VERSION "dbc-export 1 2025.20.8"

NS_ :

BS_:

BU_: ADSP APB APP APS APSB BB BMS CC CMP CMPD CP DAS DI DIF DIR DPB EPAS3P EPAS3S EPASTP EPASTS EPBL EPBR ESP EVSE FC GTW HCML HCMR HVP IBST ICR IDB LS OCS1P PARK PCS PM PMF PMR PNCD PTC RADC RCM RCM2 RCM3 RCU SCCM SCM SCS SDCR TAS TCU TPMS TRCM UI UIS UMC USM VC VCFRONT VCLEFT VCRIGHT VCSEC VEH

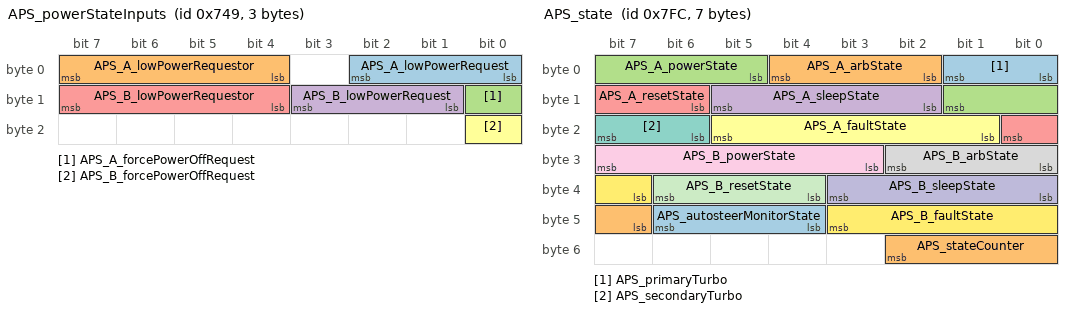
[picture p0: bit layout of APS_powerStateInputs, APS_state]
BO_ 1865 APS_powerStateInputs: 3 APS
 SG_ APS_A_lowPowerRequest : 0|3@1+ (1,0) [0|7] "" Vector__XXX
 SG_ APS_A_lowPowerRequestor : 4|4@1+ (1,0) [0|15] "" Vector__XXX
 SG_ APS_A_forcePowerOffRequest : 8|1@1+ (1,0) [0|1] "" Vector__XXX
 SG_ APS_B_lowPowerRequest : 9|3@1+ (1,0) [0|7] "" Vector__XXX
 SG_ APS_B_lowPowerRequestor : 12|4@1+ (1,0) [0|15] "" Vector__XXX
 SG_ APS_B_forcePowerOffRequest : 16|1@1+ (1,0) [0|1] "" Vector__XXX

BO_ 2044 APS_state: 7 APS
 SG_ APS_primaryTurbo : 0|2@1+ (1,0) [0|3] "" Vector__XXX
 SG_ APS_A_arbState : 2|3@1+ (1,0) [0|7] "" Vector__XXX
 SG_ APS_A_powerState : 5|5@1+ (1,0) [0|31] "" Vector__XXX
 SG_ APS_A_sleepState : 10|4@1+ (1,0) [0|15] "" Vector__XXX
 SG_ APS_A_resetState : 14|3@1+ (1,0) [0|7] "" Vector__XXX
 SG_ APS_A_faultState : 17|5@1+ (1,0) [0|31] "" Vector__XXX
 SG_ APS_secondaryTurbo : 22|2@1+ (1,0) [0|3] "" Vector__XXX
 SG_ APS_B_arbState : 24|3@1+ (1,0) [0|7] "" Vector__XXX
 SG_ APS_B_powerState : 27|5@1+ (1,0) [0|31] "" Vector__XXX
 SG_ APS_B_sleepState : 32|4@1+ (1,0) [0|15] "" Vector__XXX
 SG_ APS_B_resetState : 36|3@1+ (1,0) [0|7] "" Vector__XXX
 SG_ APS_B_faultState : 39|5@1+ (1,0) [0|31] "" Vector__XXX
 SG_ APS_autosteerMonitorState : 44|3@1+ (1,0) [0|7] "" Vector__XXX
 SG_ APS_stateCounter : 47|4@1+ (1,0) [0|15] "" Vector__XXX

BO_ 970 APS_status: 8 APS
 SG_ APS_appStatusMonitorState : 0|3@1+ (1,0) [0|7] "" Vector__XXX
 SG_ APS_vehBehaviorState : 4|4@1+ (1,0) [0|15] "" Vector__XXX
 SG_ APS_canMaster : 8|2@1+ (1,0) [0|2] "" Vector__XXX
 SG_ APS_appGpioState : 10|2@1+ (1,0) [0|3] "" Vector__XXX
 SG_ APS_eacInternalState : 12|3@1+ (1,0) [0|7] "" Vector__XXX
 SG_ APS_switchState : 15|1@1+ (1,0) [0|1] "" Vector__XXX
 SG_ APS_apbStatusMonitorState : 16|3@1+ (1,0) [0|7] "" Vector__XXX
 SG_ APS_apbGpioState : 20|2@1+ (1,0) [0|3] "" Vector__XXX
 SG_ APS_statusCounter : 22|4@1+ (1,0) [0|15] "" Vector__XXX
 SG_ APS_locLimitReason : 26|3@1+ (1,0) [0|7] "" Vector__XXX
 SG_ APS_appPowerStateRequest : 29|2@1+ (1,0) [0|3] "" Vector__XXX
 SG_ APS_appPowerStateReason : 31|4@1+ (1,0) [0|15] "" Vector__XXX
 SG_ APS_apbPowerStateRequest : 36|2@1+ (1,0) [0|3] "" Vector__XXX
 SG_ APS_apbPowerStateReason : 38|4@1+ (1,0) [0|15] "" Vector__XXX
 SG_ APS_heaterStateDebug : 43|3@1+ (1,0) [0|6] "" Vector__XXX
 SG_ APS_autosummonCounter : 46|3@1+ (1,0) [0|7] "" Vector__XXX
 SG_ APS_autosummonAlert : 49|1@1+ (1,0) [0|1] "" Vector__XXX
 SG_ APS_gpsAntennaState : 50|2@1+ (1,0) [0|3] "" Vector__XXX
 SG_ APS_arbState : 52|3@1+ (1,0) [0|7] "" Vector__XXX
 SG_ APS_socPowerOperatingMode : 55|2@1+ (1,0) [0|3] "" Vector__XXX
 SG_ APS_otherArbState : 57|3@1+ (1,0) [0|7] "" Vector__XXX

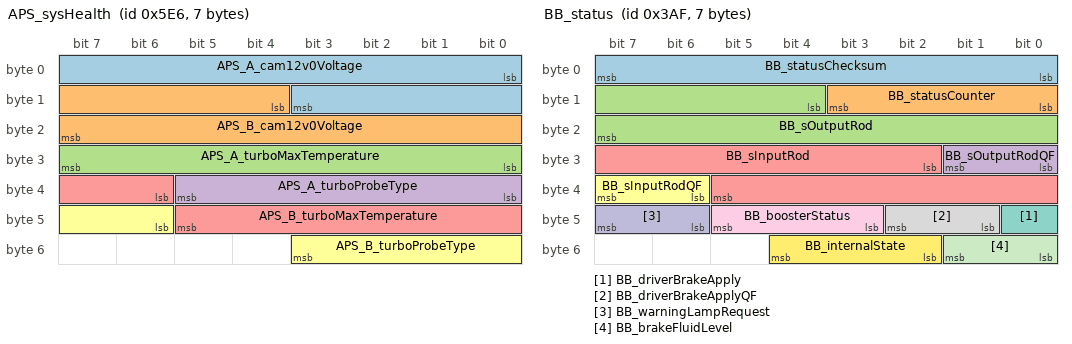
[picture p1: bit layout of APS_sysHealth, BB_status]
BO_ 1510 APS_sysHealth: 7 APS
 SG_ APS_A_cam12v0Voltage : 0|12@1+ (0.0048,0) [0|19.44] "V" Vector__XXX
 SG_ APS_B_cam12v0Voltage : 12|12@1+ (0.0048,0) [0|19.44] "V" Vector__XXX
 SG_ APS_A_turboMaxTemperature : 24|8@1- (1,0) [-128|127] "degC" Vector__XXX
 SG_ APS_A_turboProbeType : 32|6@1+ (1,0) [0|62] "" Vector__XXX
 SG_ APS_B_turboMaxTemperature : 38|8@1- (1,0) [-128|127] "degC" Vector__XXX
 SG_ APS_B_turboProbeType : 46|6@1+ (1,0) [0|62] "" Vector__XXX

BO_ 811 APS_warningMatrix0: 8 APS
 SG_ APS_w001_DEPRECATED : 0|1@1+ (1,0) [0|1] "" Vector__XXX
 SG_ APS_w002_ldwDisabled : 1|1@1+ (1,0) [0|1] "" Vector__XXX
 SG_ APS_w003_isaDisabled : 2|1@1+ (1,0) [0|1] "" Vector__XXX
 SG_ APS_w004_accDisabled : 3|1@1+ (1,0) [0|1] "" Vector__XXX
 SG_ APS_w005_fcwCancelled : 4|1@1+ (1,0) [0|1] "" Vector__XXX
 SG_ APS_w006_aebCancelled : 5|1@1+ (1,0) [0|1] "" Vector__XXX
 SG_ APS_w007_ahlbDisabled : 6|1@1+ (1,0) [0|1] "" Vector__XXX
 SG_ APS_w008_parkDisabled : 7|1@1+ (1,0) [0|1] "" Vector__XXX
 SG_ APS_w009_aebFault : 8|1@1+ (1,0) [0|1] "" Vector__XXX
 SG_ APS_w010_radcCalibIssue : 9|1@1+ (1,0) [0|1] "" Vector__XXX
 SG_ APS_w011_scaEvent : 10|1@1+ (1,0) [0|1] "" Vector__XXX
 SG_ APS_w012_Cam_BootFailure : 11|1@1+ (1,0) [0|1] "" Vector__XXX
 SG_ APS_w013_Cam_Watchdog : 12|1@1+ (1,0) [0|1] "" Vector__XXX
 SG_ APS_w014_swAssert : 13|1@1+ (1,0) [0|1] "" Vector__XXX
 SG_ APS_w015_Camera_Failsafes : 14|1@1+ (1,0) [0|1] "" Vector__XXX
 SG_ APS_w016_aeb_e_event : 15|1@1+ (1,0) [0|1] "" Vector__XXX
 SG_ APS_w017_Cam_Msg_MIA : 16|1@1+ (1,0) [0|1] "" Vector__XXX
 SG_ APS_w018_ECU_Power_Issue : 17|1@1+ (1,0) [0|1] "" Vector__XXX
 SG_ APS_w019_ECU_Stack_Overflow : 18|1@1+ (1,0) [0|1] "" Vector__XXX
 SG_ APS_w020_ECU_checkstopError : 19|1@1+ (1,0) [0|1] "" Vector__XXX
 SG_ APS_w021_ECU_Temperature_Issue : 20|1@1+ (1,0) [0|1] "" Vector__XXX
 SG_ APS_w022_ECU_EEPROM_Failure : 21|1@1+ (1,0) [0|1] "" Vector__XXX
 SG_ APS_w023_ECU_Cam_Statemismatc : 22|1@1+ (1,0) [0|1] "" Vector__XXX
 SG_ APS_w024_ECU_Watchdog_Reset : 23|1@1+ (1,0) [0|1] "" Vector__XXX
 SG_ APS_w025_LC_Steering_Override : 24|1@1+ (1,0) [0|1] "" Vector__XXX
 SG_ APS_w026_ECU_timingIssue : 25|1@1+ (1,0) [0|1] "" Vector__XXX
 SG_ APS_w027_ECU_Reset_Fault : 26|1@1+ (1,0) [0|1] "" Vector__XXX
 SG_ APS_w028_spi_rx_error : 27|1@1+ (1,0) [0|1] "" Vector__XXX
 SG_ APS_w029_spi_tx_error : 28|1@1+ (1,0) [0|1] "" Vector__XXX
 SG_ APS_w030_Heater_Issue : 29|1@1+ (1,0) [0|1] "" Vector__XXX
 SG_ APS_w031_canRxError : 30|1@1+ (1,0) [0|1] "" Vector__XXX
 SG_ APS_w032_canTxError : 31|1@1+ (1,0) [0|1] "" Vector__XXX
 SG_ APS_w033_gtwMia : 32|1@1+ (1,0) [0|1] "" Vector__XXX
 SG_ APS_w034_sccmMia : 33|1@1+ (1,0) [0|1] "" Vector__XXX
 SG_ APS_w035_espMia : 34|1@1+ (1,0) [0|1] "" Vector__XXX
 SG_ APS_w036_bdyMia : 35|1@1+ (1,0) [0|1] "" Vector__XXX
 SG_ APS_w037_camTacIssue : 36|1@1+ (1,0) [0|1] "" Vector__XXX
 SG_ APS_w038_camFailure : 37|1@1+ (1,0) [0|1] "" Vector__XXX
 SG_ APS_w039_sdm_rcm_Mia : 38|1@1+ (1,0) [0|1] "" Vector__XXX
 SG_ APS_w040_autopilotAngleSaturated : 39|1@1+ (1,0) [0|1] "" Vector__XXX
 SG_ APS_w041_autopilotRateSaturated : 40|1@1+ (1,0) [0|1] "" Vector__XXX
 SG_ APS_w042_autopilotAborting : 41|1@1+ (1,0) [0|1] "" Vector__XXX
 SG_ APS_w043_camLongRunTime : 42|1@1+ (1,0) [0|1] "" Vector__XXX
 SG_ APS_w044_appMobileyeFailure : 43|1@1+ (1,0) [0|1] "" Vector__XXX
 SG_ APS_w045_radMia : 44|1@1+ (1,0) [0|1] "" Vector__XXX
 SG_ APS_w046_eepromRecordAbsent : 45|1@1+ (1,0) [0|1] "" Vector__XXX
 SG_ APS_w047_edrEvent : 46|1@1+ (1,0) [0|1] "" Vector__XXX
 SG_ APS_w048_DAS_Features_Disabled : 47|1@1+ (1,0) [0|1] "" Vector__XXX
 SG_ APS_w049_eyeqVersionMismatch : 48|1@1+ (1,0) [0|1] "" Vector__XXX
 SG_ APS_w050_aeb_event : 49|1@1+ (1,0) [0|1] "" Vector__XXX
 SG_ APS_w051_radcEcuIssue : 50|1@1+ (1,0) [0|1] "" Vector__XXX
 SG_ APS_w052_radcSensorIssue : 51|1@1+ (1,0) [0|1] "" Vector__XXX
 SG_ APS_w053_radcCommIssue : 52|1@1+ (1,0) [0|1] "" Vector__XXX
 SG_ APS_w054_camAutofix : 53|1@1+ (1,0) [0|1] "" Vector__XXX
 SG_ APS_w055_radcVersionMismatch : 54|1@1+ (1,0) [0|1] "" Vector__XXX
 SG_ APS_w056_diMia : 55|1@1+ (1,0) [0|1] "" Vector__XXX
 SG_ APS_w057_mcuMia : 56|1@1+ (1,0) [0|1] "" Vector__XXX
 SG_ APS_w058_epbMia : 57|1@1+ (1,0) [0|1] "" Vector__XXX
 SG_ APS_w059_parkMia : 58|1@1+ (1,0) [0|1] "" Vector__XXX
 SG_ APS_w060_fcw_event : 59|1@1+ (1,0) [0|1] "" Vector__XXX
 SG_ APS_w061_tasMia : 60|1@1+ (1,0) [0|1] "" Vector__XXX
 SG_ APS_w062_radcAlignment : 61|1@1+ (1,0) [0|1] "" Vector__XXX
 SG_ APS_w063_parkVersionMismatch : 62|1@1+ (1,0) [0|1] "" Vector__XXX
 SG_ APS_w064_epasMia : 63|1@1+ (1,0) [0|1] "" Vector__XXX

BO_ 876 APS_warningMatrix1: 8 APS
 SG_ APS_w065_deserializerOvercurrent : 0|1@1+ (1,0) [0|1] "" Vector__XXX
 SG_ APS_w066_deserializerLockLost : 1|1@1+ (1,0) [0|1] "" Vector__XXX
 SG_ APS_w067_steeringAlignment : 2|1@1+ (1,0) [0|1] "" Vector__XXX
 SG_ APS_w068_vlInconsistency : 3|1@1+ (1,0) [0|1] "" Vector__XXX
 SG_ APS_w069_apcSpaceMasked : 4|1@1+ (1,0) [0|1] "" Vector__XXX
 SG_ APS_w070_apcIncompleteCal : 5|1@1+ (1,0) [0|1] "" Vector__XXX
 SG_ APS_w071_selfparkStarted : 6|1@1+ (1,0) [0|1] "" Vector__XXX
 SG_ APS_w072_selfparkComplete : 7|1@1+ (1,0) [0|1] "" Vector__XXX
 SG_ APS_w073_issueEscalatedLDW : 8|1@1+ (1,0) [0|1] "" Vector__XXX
 SG_ APS_w074_inPathStationaryObst : 9|1@1+ (1,0) [0|1] "" Vector__XXX
 SG_ APS_w075_scMia : 10|1@1+ (1,0) [0|1] "" Vector__XXX
 SG_ APS_w076_mobilEyeSetC : 11|1@1+ (1,0) [0|1] "" Vector__XXX
 SG_ APS_w077_pmmActive : 12|1@1+ (1,0) [0|1] "" Vector__XXX
 SG_ APS_w078_pmmActive2 : 13|1@1+ (1,0) [0|1] "" Vector__XXX
 SG_ APS_w079_edrAvailable : 14|1@1+ (1,0) [0|1] "" Vector__XXX
 SG_ APS_w080_accFailedActivation : 15|1@1+ (1,0) [0|1] "" Vector__XXX
 SG_ APS_w081_pmmActiveBraking : 16|1@1+ (1,0) [0|1] "" Vector__XXX
 SG_ APS_w082_inPathFSviolation : 17|1@1+ (1,0) [0|1] "" Vector__XXX
 SG_ APS_w083_inPathRADObject : 18|1@1+ (1,0) [0|1] "" Vector__XXX
 SG_ APS_w084_pmmIPSO : 19|1@1+ (1,0) [0|1] "" Vector__XXX
 SG_ APS_w085_pmmSteering : 20|1@1+ (1,0) [0|1] "" Vector__XXX
 SG_ APS_w086_robCollision : 21|1@1+ (1,0) [0|1] "" Vector__XXX
 SG_ APS_w087_DEPRECATED : 22|1@1+ (1,0) [0|1] "" Vector__XXX
 SG_ APS_w088_DEPRECATED : 23|1@1+ (1,0) [0|1] "" Vector__XXX
 SG_ APS_w089_DEPRECATED : 24|1@1+ (1,0) [0|1] "" Vector__XXX
 SG_ APS_w090_DEPRECATED : 25|1@1+ (1,0) [0|1] "" Vector__XXX
 SG_ APS_w091_DEPRECATED : 26|1@1+ (1,0) [0|1] "" Vector__XXX
 SG_ APS_w092_DEPRECATED : 27|1@1+ (1,0) [0|1] "" Vector__XXX
 SG_ APS_w093_DEPRECATED : 28|1@1+ (1,0) [0|1] "" Vector__XXX
 SG_ APS_w094_DEPRECATED : 29|1@1+ (1,0) [0|1] "" Vector__XXX
 SG_ APS_w095_DEPRECATED : 30|1@1+ (1,0) [0|1] "" Vector__XXX
 SG_ APS_w096_DEPRECATED : 31|1@1+ (1,0) [0|1] "" Vector__XXX
 SG_ APS_w097_DEPRECATED : 32|1@1+ (1,0) [0|1] "" Vector__XXX
 SG_ APS_w098_DEPRECATED : 33|1@1+ (1,0) [0|1] "" Vector__XXX
 SG_ APS_w099_DEPRECATED : 34|1@1+ (1,0) [0|1] "" Vector__XXX
 SG_ APS_w100_DEPRECATED : 35|1@1+ (1,0) [0|1] "" Vector__XXX
 SG_ APS_w101_DEPRECATED : 36|1@1+ (1,0) [0|1] "" Vector__XXX
 SG_ APS_w102_DEPRECATED : 37|1@1+ (1,0) [0|1] "" Vector__XXX
 SG_ APS_w103_robExperimentalAEB : 38|1@1+ (1,0) [0|1] "" Vector__XXX
 SG_ APS_w104_DEPRECATED : 39|1@1+ (1,0) [0|1] "" Vector__XXX
 SG_ APS_w105_DEPRECATED : 40|1@1+ (1,0) [0|1] "" Vector__XXX
 SG_ APS_w106_torsionBarOffset : 41|1@1+ (1,0) [0|1] "" Vector__XXX

BO_ 1113 APS_warningMatrix2: 8 APS
 SG_ APS_w129_ECU_Power_Issue : 0|1@1+ (1,0) [0|1] "" Vector__XXX
 SG_ APS_w130_ECU_Thermal_Issue : 1|1@1+ (1,0) [0|1] "" Vector__XXX
 SG_ APS_w131_trap_exception : 2|1@1+ (1,0) [0|1] "" Vector__XXX
 SG_ APS_w132_appVersionMismatch : 3|1@1+ (1,0) [0|1] "" Vector__XXX
 SG_ APS_w133_ETHSwitchError : 4|1@1+ (1,0) [0|1] "" Vector__XXX
 SG_ APS_w134_appMia : 5|1@1+ (1,0) [0|1] "" Vector__XXX
 SG_ APS_w135_appCritical : 6|1@1+ (1,0) [0|1] "" Vector__XXX
 SG_ APS_w136_gpsDisabled : 7|1@1+ (1,0) [0|1] "" Vector__XXX
 SG_ APS_w137_gpsFaultReset : 8|1@1+ (1,0) [0|1] "" Vector__XXX
 SG_ APS_w138_gpsComIssue : 9|1@1+ (1,0) [0|1] "" Vector__XXX
 SG_ APS_w139_udpBufferOverflow : 10|1@1+ (1,0) [0|1] "" Vector__XXX
 SG_ APS_w140_vcfrontMiaVehicleBus : 11|1@1+ (1,0) [0|1] "" Vector__XXX
 SG_ APS_w141_rcmMiaPartyBus : 12|1@1+ (1,0) [0|1] "" Vector__XXX
 SG_ APS_w142_diMiaPartyBus : 13|1@1+ (1,0) [0|1] "" Vector__XXX
 SG_ APS_w143_espMiaPartyBus : 14|1@1+ (1,0) [0|1] "" Vector__XXX
 SG_ APS_w144_vcleftMiaPartyBus : 15|1@1+ (1,0) [0|1] "" Vector__XXX
 SG_ APS_w145_vcrightMiaPartyBus : 16|1@1+ (1,0) [0|1] "" Vector__XXX
 SG_ APS_w146_epas3pMiaPartyBus : 17|1@1+ (1,0) [0|1] "" Vector__XXX
 SG_ APS_w147_vcleftMiaVehBus : 18|1@1+ (1,0) [0|1] "" Vector__XXX
 SG_ APS_w148_vcrightMiaVehBus : 19|1@1+ (1,0) [0|1] "" Vector__XXX
 SG_ APS_w149_epblMiaVehBus : 20|1@1+ (1,0) [0|1] "" Vector__XXX
 SG_ APS_w150_sccmMiaVehBus : 21|1@1+ (1,0) [0|1] "" Vector__XXX
 SG_ APS_w151_apRecovered : 22|1@1+ (1,0) [0|1] "" Vector__XXX
 SG_ APS_w152_gpsFusionStatus : 23|1@1+ (1,0) [0|1] "" Vector__XXX
 SG_ APS_w153_eacInhibit : 24|1@1+ (1,0) [0|1] "" Vector__XXX
 SG_ APS_w155_ethLwipError : 26|1@1+ (1,0) [0|1] "" Vector__XXX
 SG_ APS_w156_lwipAssert : 27|1@1+ (1,0) [0|1] "" Vector__XXX
 SG_ APS_w157_autopilotReboot : 28|1@1+ (1,0) [0|1] "" Vector__XXX
 SG_ APS_w158_apbMia : 29|1@1+ (1,0) [0|1] "" Vector__XXX
 SG_ APS_w159_apbCritical : 30|1@1+ (1,0) [0|1] "" Vector__XXX
 SG_ APS_w160_apbVersionMismatch : 31|1@1+ (1,0) [0|1] "" Vector__XXX
 SG_ APS_w161_gpsAntennaDisconnected : 32|1@1+ (1,0) [0|1] "" Vector__XXX
 SG_ APS_w162_TurboA_DisRegPgoodErr : 33|1@1+ (1,0) [0|1] "" Vector__XXX
 SG_ APS_w163_TurboA_DisRegNFault : 34|1@1+ (1,0) [0|1] "" Vector__XXX
 SG_ APS_w164_TurboA_12VFuseFault : 35|1@1+ (1,0) [0|1] "" Vector__XXX
 SG_ APS_w165_TurboA_Temp_NOS : 36|1@1+ (1,0) [0|1] "" Vector__XXX
 SG_ APS_w166_TurboA_SMSLockStepErr : 37|1@1+ (1,0) [0|1] "" Vector__XXX
 SG_ APS_w167_TurboA_TMU_Throttle : 38|1@1+ (1,0) [0|1] "" Vector__XXX
 SG_ APS_w168_TurboA_SMS_WDOG : 39|1@1+ (1,0) [0|1] "" Vector__XXX
 SG_ APS_w169_TurboA_SCS_LKUP : 40|1@1+ (1,0) [0|1] "" Vector__XXX
 SG_ APS_w170_TurboA_A72_watchdog : 41|1@1+ (1,0) [0|1] "" Vector__XXX
 SG_ APS_w171_TurboA_SMS_taskUtilErr : 42|1@1+ (1,0) [0|1] "" Vector__XXX
 SG_ APS_w172_apFeaturesUnavailable : 43|1@1+ (1,0) [0|1] "" Vector__XXX
 SG_ APS_w178_TurboB_DisRegPgoodErr : 49|1@1+ (1,0) [0|1] "" Vector__XXX
 SG_ APS_w179_TurboB_DisRegNFault : 50|1@1+ (1,0) [0|1] "" Vector__XXX
 SG_ APS_w180_TurboB_12VFuseFault : 51|1@1+ (1,0) [0|1] "" Vector__XXX
 SG_ APS_w181_TurboB_Temp_NOS : 52|1@1+ (1,0) [0|1] "" Vector__XXX
 SG_ APS_w182_TurboB_SMSLockStepErr : 53|1@1+ (1,0) [0|1] "" Vector__XXX
 SG_ APS_w183_TurboB_TMU_Throttle : 54|1@1+ (1,0) [0|1] "" Vector__XXX
 SG_ APS_w184_TurboB_SMS_WDOG : 55|1@1+ (1,0) [0|1] "" Vector__XXX
 SG_ APS_w185_TurboB_SCS_LKUP : 56|1@1+ (1,0) [0|1] "" Vector__XXX
 SG_ APS_w186_TurboB_A72_watchdog : 57|1@1+ (1,0) [0|1] "" Vector__XXX
 SG_ APS_w187_TurboB_SMS_taskUtilErr : 58|1@1+ (1,0) [0|1] "" Vector__XXX
 SG_ APS_w188_otherTurboUartMIA : 59|1@1+ (1,0) [0|1] "" Vector__XXX
 SG_ APS_w189_vcfrontMiaPartyBus : 60|1@1+ (1,0) [0|1] "" Vector__XXX
 SG_ APS_w190_iboosterMia : 61|1@1+ (1,0) [0|1] "" Vector__XXX
 SG_ APS_w191_timesyncError : 62|1@1+ (1,0) [0|1] "" Vector__XXX
 SG_ APS_w192_CANFault : 63|1@1+ (1,0) [0|1] "" Vector__XXX

BO_ 848 APS_warningMatrix3: 8 APS
 SG_ APS_w193_camWindshieldUnclean : 0|1@1+ (1,0) [0|1] "" Vector__XXX
 SG_ APS_w194_accDriverResumeRqrd : 1|1@1+ (1,0) [0|1] "" Vector__XXX
 SG_ APS_w195_scwUnavailable : 2|1@1+ (1,0) [0|1] "" Vector__XXX
 SG_ APS_w196_stopSignWarning : 3|1@1+ (1,0) [0|1] "" Vector__XXX
 SG_ APS_w197_redLightWarning : 4|1@1+ (1,0) [0|1] "" Vector__XXX
 SG_ APS_w198_tsrUnavailable : 5|1@1+ (1,0) [0|1] "" Vector__XXX
 SG_ APS_w199_apcAbort : 6|1@1+ (1,0) [0|1] "" Vector__XXX
 SG_ APS_w200_lcSlowdown : 7|1@1+ (1,0) [0|1] "" Vector__XXX
 SG_ APS_w201_lcAborting : 8|1@1+ (1,0) [0|1] "" Vector__XXX
 SG_ APS_w202_scwNoisyEnvironment : 9|1@1+ (1,0) [0|1] "" Vector__XXX
 SG_ APS_w203_apcActivation : 10|1@1+ (1,0) [0|1] "" Vector__XXX
 SG_ APS_w204_apcFinalFront : 11|1@1+ (1,0) [0|1] "" Vector__XXX
 SG_ APS_w205_apcFinalRear : 12|1@1+ (1,0) [0|1] "" Vector__XXX
 SG_ APS_w206_autosteerNotEnabled : 13|1@1+ (1,0) [0|1] "" Vector__XXX
 SG_ APS_w207_autosteerUnavailable : 14|1@1+ (1,0) [0|1] "" Vector__XXX
 SG_ APS_w208_rackDetected : 15|1@1+ (1,0) [0|1] "" Vector__XXX
 SG_ APS_w209_autoSummonRequest : 16|1@1+ (1,0) [0|1] "" Vector__XXX
 SG_ APS_w210_camObstrcted : 17|1@1+ (1,0) [0|1] "" Vector__XXX
 SG_ APS_w211_accNoSeatBelt : 18|1@1+ (1,0) [0|1] "" Vector__XXX
 SG_ APS_w212_lcUnavailableStrikeOut : 19|1@1+ (1,0) [0|1] "" Vector__XXX
 SG_ APS_w213_autosteerStruckOut : 20|1@1+ (1,0) [0|1] "" Vector__XXX
 SG_ APS_w214_driverNotIntracting : 21|1@1+ (1,0) [0|1] "" Vector__XXX
 SG_ APS_w215_contDriverNotIntracting : 22|1@1+ (1,0) [0|1] "" Vector__XXX
 SG_ APS_w216_driverOverriding : 23|1@1+ (1,0) [0|1] "" Vector__XXX
 SG_ APS_w217_lcUnavailableSpeeding : 24|1@1+ (1,0) [0|1] "" Vector__XXX
 SG_ APS_w218_lcSpeedExceededLimit : 25|1@1+ (1,0) [0|1] "" Vector__XXX
 SG_ APS_w219_lcTempUnavailableSpeed : 26|1@1+ (1,0) [0|1] "" Vector__XXX
 SG_ APS_w220_lcTempUnavailableRoad : 27|1@1+ (1,0) [0|1] "" Vector__XXX
 SG_ APS_w221_accRadarBlind : 28|1@1+ (1,0) [0|1] "" Vector__XXX
 SG_ APS_w222_accCameraBlind : 29|1@1+ (1,0) [0|1] "" Vector__XXX
 SG_ APS_w223_accObjectInPath : 30|1@1+ (1,0) [0|1] "" Vector__XXX
 SG_ APS_w224_accCameraCalibration : 31|1@1+ (1,0) [0|1] "" Vector__XXX
 SG_ APS_w225_lcDegradedVisSpeedLmt : 32|1@1+ (1,0) [0|1] "" Vector__XXX
 SG_ APS_w226_lcCamCalNeededSpeedLmt : 33|1@1+ (1,0) [0|1] "" Vector__XXX
 SG_ APS_w227_virtualWallBlocked : 34|1@1+ (1,0) [0|1] "" Vector__XXX
 SG_ APS_w228_DEPRECATED : 35|1@1+ (1,0) [0|1] "" Vector__XXX
 SG_ APS_w229_alcUltrasoundDamaged : 36|1@1+ (1,0) [0|1] "" Vector__XXX
 SG_ APS_w230_alcUltrasoundBlocked : 37|1@1+ (1,0) [0|1] "" Vector__XXX
 SG_ APS_w231_idfEvent : 38|1@1+ (1,0) [0|1] "" Vector__XXX
 SG_ APS_w232_laneChangeRequested : 39|1@1+ (1,0) [0|1] "" Vector__XXX
 SG_ APS_w235_a72LoopDetected : 42|1@1+ (1,0) [0|1] "" Vector__XXX
 SG_ APS_w236_canSharedMemError : 43|1@1+ (1,0) [0|1] "" Vector__XXX
 SG_ APS_w237_faultMgrEventDetected : 44|1@1+ (1,0) [0|1] "" Vector__XXX
 SG_ APS_w238_resetReason : 45|1@1+ (1,0) [0|1] "" Vector__XXX
 SG_ APS_w241_ddrInitFailures : 48|1@1+ (1,0) [0|1] "" Vector__XXX
 SG_ APS_w242_tripMBISTFailure : 49|1@1+ (1,0) [0|1] "" Vector__XXX
 SG_ APS_w243_tripHWErrorStatus : 50|1@1+ (1,0) [0|1] "" Vector__XXX
 SG_ APS_w244_gpuHWFaultStatus : 51|1@1+ (1,0) [0|1] "" Vector__XXX
 SG_ APS_w245_eloopRxFromUnexpectedSo : 52|1@1+ (1,0) [0|1] "" Vector__XXX
 SG_ APS_w246_ethloopSwitchPortLinkDo : 53|1@1+ (1,0) [0|1] "" Vector__XXX
 SG_ APS_w247_ethernetFrameError : 54|1@1+ (1,0) [0|1] "" Vector__XXX
 SG_ APS_w248_ethloopSwitchPoorSqi : 55|1@1+ (1,0) [0|1] "" Vector__XXX
 SG_ APS_w249_ufsFailures : 56|1@1+ (1,0) [0|1] "" Vector__XXX
 SG_ APS_w250_ethloopSwitchMemUsageTo : 57|1@1+ (1,0) [0|1] "" Vector__XXX
 SG_ APS_w251_ethloopSwitchMemUsageTo : 58|1@1+ (1,0) [0|1] "" Vector__XXX
 SG_ APS_w252_ethSwitchPortLinkDown : 59|1@1+ (1,0) [0|1] "" Vector__XXX
 SG_ APS_w253_powerStateTimeout : 60|1@1+ (1,0) [0|1] "" Vector__XXX
 SG_ APS_w254_sleepStateTimeout : 61|1@1+ (1,0) [0|1] "" Vector__XXX
 SG_ APS_w255_bootHealth : 62|1@1+ (1,0) [0|1] "" Vector__XXX

BO_ 784 APS_warningMatrix4: 8 APS
 SG_ APS_w257_assertFailure : 0|1@1+ (1,0) [0|1] "" Vector__XXX
 SG_ APS_w258_qspiFlashSectorChecksum : 1|1@1+ (1,0) [0|1] "" Vector__XXX
 SG_ APS_w259_qspiFailure : 2|1@1+ (1,0) [0|1] "" Vector__XXX
 SG_ APS_w260_pgoodFailure : 3|1@1+ (1,0) [0|1] "" Vector__XXX
 SG_ APS_w261_vrmFaultGrpA : 4|1@1+ (1,0) [0|1] "" Vector__XXX
 SG_ APS_w262_vrmFaultGrpB : 5|1@1+ (1,0) [0|1] "" Vector__XXX
 SG_ APS_w263_vrmFaultGrpC : 6|1@1+ (1,0) [0|1] "" Vector__XXX
 SG_ APS_w264_ddrPhy0Failures : 7|1@1+ (1,0) [0|1] "" Vector__XXX
 SG_ APS_w265_ddrPhy1Failures : 8|1@1+ (1,0) [0|1] "" Vector__XXX
 SG_ APS_w266_ddrPhy2Failures : 9|1@1+ (1,0) [0|1] "" Vector__XXX
 SG_ APS_w267_ddrPhy3Failures : 10|1@1+ (1,0) [0|1] "" Vector__XXX
 SG_ APS_w268_ddrControllerFailures : 11|1@1+ (1,0) [0|1] "" Vector__XXX
 SG_ APS_w269_ethSwitchRxPageCountToo : 12|1@1+ (1,0) [0|1] "" Vector__XXX
 SG_ APS_w270_ethSwitchRxPageCountToo : 13|1@1+ (1,0) [0|1] "" Vector__XXX
 SG_ APS_w271_ddrScheduler0EccErrors : 14|1@1+ (1,0) [0|1] "" Vector__XXX
 SG_ APS_w272_ddrScheduler1EccErrors : 15|1@1+ (1,0) [0|1] "" Vector__XXX
 SG_ APS_w273_ddrScheduler2EccErrors : 16|1@1+ (1,0) [0|1] "" Vector__XXX
 SG_ APS_w274_ddrScheduler3EccErrors : 17|1@1+ (1,0) [0|1] "" Vector__XXX
 SG_ APS_w275_ddrScheduler4EccErrors : 18|1@1+ (1,0) [0|1] "" Vector__XXX
 SG_ APS_w276_ddrScheduler5EccErrors : 19|1@1+ (1,0) [0|1] "" Vector__XXX
 SG_ APS_w277_ddrScheduler6EccErrors : 20|1@1+ (1,0) [0|1] "" Vector__XXX
 SG_ APS_w278_ddrScheduler7EccErrors : 21|1@1+ (1,0) [0|1] "" Vector__XXX
 SG_ APS_w279_ufsPartitionError : 22|1@1+ (1,0) [0|1] "" Vector__XXX
 SG_ APS_w280_pepsMia : 23|1@1+ (1,0) [0|1] "" Vector__XXX
 SG_ APS_w281_rsaMia : 24|1@1+ (1,0) [0|1] "" Vector__XXX
 SG_ APS_w282_smmuError : 25|1@1+ (1,0) [0|1] "" Vector__XXX
 SG_ APS_w284_cam12VBuckBoostAPwrIssu : 27|1@1+ (1,0) [0|1] "" Vector__XXX
 SG_ APS_w285_cam12VBuckBoostBPwrIssu : 28|1@1+ (1,0) [0|1] "" Vector__XXX
 SG_ APS_w286_cam12VEFuseAPrimaryIssu : 29|1@1+ (1,0) [0|1] "" Vector__XXX
 SG_ APS_w287_cam12VEFuseASecondaryIs : 30|1@1+ (1,0) [0|1] "" Vector__XXX
 SG_ APS_w288_brakeboosterMia : 31|1@1+ (1,0) [0|1] "" Vector__XXX
 SG_ APS_w289_turboTemperatureWarning : 32|1@1+ (1,0) [0|1] "" Vector__XXX
 SG_ APS_w290_cam12VBuckBoostBPwrRing : 33|1@1+ (1,0) [0|1] "" Vector__XXX

BO_ 943 BB_status: 7 BB
 SG_ BB_statusChecksum : 0|8@1+ (1,0) [0|255] "" Vector__XXX
 SG_ BB_statusCounter : 8|4@1+ (1,0) [0|15] "" Vector__XXX
 SG_ BB_sOutputRod : 12|12@1+ (0.015625,-5) [-5|47] "mm" Vector__XXX
 SG_ BB_sOutputRodQF : 24|2@1+ (1,0) [0|3] "" Vector__XXX
 SG_ BB_sInputRod : 26|12@1+ (0.015625,-5) [-5|47] "mm" Vector__XXX
 SG_ BB_sInputRodQF : 38|2@1+ (1,0) [0|3] "" Vector__XXX
 SG_ BB_driverBrakeApply : 40|1@1+ (1,0) [0|1] "" Vector__XXX
 SG_ BB_driverBrakeApplyQF : 41|2@1+ (1,0) [0|3] "" Vector__XXX
 SG_ BB_boosterStatus : 43|3@1+ (1,0) [0|7] "" Vector__XXX
 SG_ BB_warningLampRequest : 46|2@1+ (1,0) [0|3] "" Vector__XXX
 SG_ BB_brakeFluidLevel : 48|2@1+ (1,0) [0|3] "" Vector__XXX
 SG_ BB_internalState : 50|3@1+ (1,0) [0|7] "" Vector__XXX

BO_TX_BU_ 1865 : APS;
BO_TX_BU_ 2044 : APS;
BO_TX_BU_ 970 : APS;
BO_TX_BU_ 1510 : APS;
BO_TX_BU_ 811 : APS;
BO_TX_BU_ 876 : APS;
BO_TX_BU_ 1113 : APS;
BO_TX_BU_ 848 : APS;
BO_TX_BU_ 784 : APS;
BO_TX_BU_ 943 : BB;
CM_ BO_ 1865 "Driver assistance computer (secondary) message: power state inputs";
CM_ SG_ 1865 APS_A_lowPowerRequest "Indicates Autopilot Secondary Processor (APS) low power state request presence.";
CM_ SG_ 1865 APS_A_lowPowerRequestor "Indicates who initiated the Autopilot Secondary Processor (APS) low power request.";
CM_ SG_ 1865 APS_A_forcePowerOffRequest "Driver assistance computer (secondary): a force power off request";
CM_ SG_ 1865 APS_B_lowPowerRequest "Indicates Autopilot Secondary Processor (APS) low power state request presence.";
CM_ SG_ 1865 APS_B_lowPowerRequestor "Indicates who initiated the Autopilot Secondary Processor (APS) low power request.";
CM_ SG_ 1865 APS_B_forcePowerOffRequest "Driver assistance computer (secondary): b force power off request";
CM_ BO_ 2044 "Driver assistance computer (secondary) message: state";
CM_ SG_ 2044 APS_primaryTurbo "Which of the two Turbos currently holds the primary role.";
CM_ SG_ 2044 APS_A_arbState "The state of the arbitration state machine of Turbo A.";
CM_ SG_ 2044 APS_A_powerState "The state of the power state machine of Turbo A.";
CM_ SG_ 2044 APS_A_sleepState "The state of the sleep state machine of Turbo A.";
CM_ SG_ 2044 APS_A_resetState "The state of the reset state machine of Turbo A.";
CM_ SG_ 2044 APS_A_faultState "The state of the fault state machine of Turbo A.";
CM_ SG_ 2044 APS_secondaryTurbo "Which of the two Turbos currently holds the secondary role.";
CM_ SG_ 2044 APS_B_arbState "The state of the arbitration state machine of Turbo B.";
CM_ SG_ 2044 APS_B_powerState "The state of the power state machine of Turbo B.";
CM_ SG_ 2044 APS_B_sleepState "The state of the sleep state machine of Turbo B.";
CM_ SG_ 2044 APS_B_resetState "The state of the reset state machine of Turbo B.";
CM_ SG_ 2044 APS_B_faultState "The state of the fault state machine of Turbo B.";
CM_ SG_ 2044 APS_autosteerMonitorState "Driver assistance computer (secondary): autosteer monitor state";
CM_ SG_ 2044 APS_stateCounter "Driver assistance computer (secondary): state counter";
CM_ BO_ 970 "Driver assistance computer (secondary) message: status";
CM_ SG_ 970 APS_appStatusMonitorState "The current status of APE, indicates the health of the stack on the APE";
CM_ SG_ 970 APS_vehBehaviorState "Driver assistance computer (secondary): veh behavior state";
CM_ SG_ 970 APS_canMaster "Indicates which of the autopilot computers is currently controlling outgoing CAN traffic.; raw 3 = signal not available (SNA)";
CM_ SG_ 970 APS_appGpioState "The GPIO state of APEA, indicates the health of the primary Parker (HW2 and HW2.5)";
CM_ SG_ 970 APS_eacInternalState "Indicates the internal state of the external angle control monitor running on Aurix.";
CM_ SG_ 970 APS_switchState "Driver assistance computer (secondary): switch state";
CM_ SG_ 970 APS_apbStatusMonitorState "The current status of APEB, indicates the health of the stack on the APEB";
CM_ SG_ 970 APS_apbGpioState "The GPIO state of APEB, indicates the health of the secondary Parker (HW2.5 only)";
CM_ SG_ 970 APS_statusCounter "Driver assistance computer (secondary): status counter";
CM_ SG_ 970 APS_locLimitReason "Indicates why longitudinal control limits are currently not relaxed";
CM_ SG_ 970 APS_appPowerStateRequest "Indicates ap primary power state request";
CM_ SG_ 970 APS_appPowerStateReason "Indicates ap primary power state reason";
CM_ SG_ 970 APS_apbPowerStateRequest "Indicates ap backup power state request";
CM_ SG_ 970 APS_apbPowerStateReason "Indicates ap backup power state reason";
CM_ SG_ 970 APS_heaterStateDebug "Driver assistance computer (secondary): heater state debug; raw 7 = signal not available (SNA)";
CM_ SG_ 970 APS_autosummonCounter "Driver assistance computer (secondary): autosummon counter";
CM_ SG_ 970 APS_autosummonAlert "Driver assistance computer (secondary): autosummon alert";
CM_ SG_ 970 APS_gpsAntennaState "Driver assistance computer (secondary): gps antenna state";
CM_ SG_ 970 APS_arbState "Reports the state of the arbitration state machine of this System on Chip (SoC).";
CM_ SG_ 970 APS_socPowerOperatingMode "Reports the total number of System on Chips (SoCs) that are powered on to provide support for active Autopilot features.";
CM_ SG_ 970 APS_otherArbState "Reports the state of the arbitration state machine of the other System on Chip (SoC). Lets the current SoC know the state of the other SoC to achieve safer operations.";
CM_ BO_ 1510 "Driver assistance computer (secondary) message: sys health";
CM_ SG_ 1510 APS_A_cam12v0Voltage "Measures the 12V camera power supply voltage for Autopilot Secondary Processor (APS) Turbo A; raw 4095 = signal not available (SNA)";
CM_ SG_ 1510 APS_B_cam12v0Voltage "Measures the 12V camera power supply voltage for Autopilot Secondary Processor (APS) Turbo B; raw 4095 = signal not available (SNA)";
CM_ SG_ 1510 APS_A_turboMaxTemperature "Reports the maximum temperature recorded by Autopilot Secondary Processor (APS) unit A.; raw 128 = signal not available (SNA)";
CM_ SG_ 1510 APS_A_turboProbeType "Driver assistance computer (secondary): a turbo probe type; raw 63 = signal not available (SNA)";
CM_ SG_ 1510 APS_B_turboMaxTemperature "Reports the maximum temperature recorded by Autopilot Secondary Processor (APS) unit B.; raw 128 = signal not available (SNA)";
CM_ SG_ 1510 APS_B_turboProbeType "Driver assistance computer (secondary): b turbo probe type; raw 63 = signal not available (SNA)";
CM_ BO_ 811 "Driver assistance computer (secondary) message: warning matrix0";
CM_ SG_ 811 APS_w001_DEPRECATED "Driver assistance computer (secondary): w001 DEPRECATED";
CM_ SG_ 811 APS_w002_ldwDisabled "Driver assistance computer (secondary): w002 ldw disabled";
CM_ SG_ 811 APS_w003_isaDisabled "Driver assistance computer (secondary): w003 isa disabled";
CM_ SG_ 811 APS_w004_accDisabled "Driver assistance computer (secondary): w004 acc disabled";
CM_ SG_ 811 APS_w005_fcwCancelled "Driver assistance computer (secondary): w005 fcw cancelled";
CM_ SG_ 811 APS_w006_aebCancelled "Driver assistance computer (secondary): w006 aeb cancelled";
CM_ SG_ 811 APS_w007_ahlbDisabled "Driver assistance computer (secondary): w007 ahlb disabled";
CM_ SG_ 811 APS_w008_parkDisabled "Driver assistance computer (secondary): w008 park disabled";
CM_ SG_ 811 APS_w009_aebFault "Driver assistance computer (secondary): w009 aeb fault";
CM_ SG_ 811 APS_w010_radcCalibIssue "Driver assistance computer (secondary): w010 radc calib issue";
CM_ SG_ 811 APS_w011_scaEvent "Driver assistance computer (secondary): w011 sca event";
CM_ SG_ 811 APS_w012_Cam_BootFailure "Driver assistance computer (secondary): w012 cam boot failure";
CM_ SG_ 811 APS_w013_Cam_Watchdog "Driver assistance computer (secondary): w013 cam watchdog";
CM_ SG_ 811 APS_w014_swAssert "Driver assistance computer (secondary): w014 sw assert";
CM_ SG_ 811 APS_w015_Camera_Failsafes "Driver assistance computer (secondary): w015 camera failsafes";
CM_ SG_ 811 APS_w016_aeb_e_event "Driver assistance computer (secondary): w016 aeb e event";
CM_ SG_ 811 APS_w017_Cam_Msg_MIA "Driver assistance computer (secondary): w017 cam msg MIA";
CM_ SG_ 811 APS_w018_ECU_Power_Issue "Driver assistance computer (secondary): w018 ECU power issue";
CM_ SG_ 811 APS_w019_ECU_Stack_Overflow "Driver assistance computer (secondary): w019 ECU stack overflow";
CM_ SG_ 811 APS_w020_ECU_checkstopError "Driver assistance computer (secondary): w020 ECU checkstop error";
CM_ SG_ 811 APS_w021_ECU_Temperature_Issue "Driver assistance computer (secondary): w021 ECU temperature issue";
CM_ SG_ 811 APS_w022_ECU_EEPROM_Failure "Driver assistance computer (secondary): w022 ECU EEPROM failure";
CM_ SG_ 811 APS_w023_ECU_Cam_Statemismatc "Driver assistance computer (secondary): w023 ECU cam statemismatc";
CM_ SG_ 811 APS_w024_ECU_Watchdog_Reset "Driver assistance computer (secondary): w024 ECU watchdog reset";
CM_ SG_ 811 APS_w025_LC_Steering_Override "Driver assistance computer (secondary): w025 LC steering override";
CM_ SG_ 811 APS_w026_ECU_timingIssue "Driver assistance computer (secondary): w026 ECU timing issue";
CM_ SG_ 811 APS_w027_ECU_Reset_Fault "Driver assistance computer (secondary): w027 ECU reset fault";
CM_ SG_ 811 APS_w028_spi_rx_error "Driver assistance computer (secondary): w028 spi rx error";
CM_ SG_ 811 APS_w029_spi_tx_error "Driver assistance computer (secondary): w029 spi tx error";
CM_ SG_ 811 APS_w030_Heater_Issue "Driver assistance computer (secondary): w030 heater issue";
CM_ SG_ 811 APS_w031_canRxError "Driver assistance computer (secondary): w031 can rx error";
CM_ SG_ 811 APS_w032_canTxError "Driver assistance computer (secondary): w032 can tx error";
CM_ SG_ 811 APS_w033_gtwMia "Driver assistance computer (secondary): w033 gtw mia";
CM_ SG_ 811 APS_w034_sccmMia "Driver assistance computer (secondary): w034 sccm mia";
CM_ SG_ 811 APS_w035_espMia "Driver assistance computer (secondary): w035 esp mia";
CM_ SG_ 811 APS_w036_bdyMia "Driver assistance computer (secondary): w036 bdy mia";
CM_ SG_ 811 APS_w037_camTacIssue "Driver assistance computer (secondary): w037 cam tac issue";
CM_ SG_ 811 APS_w038_camFailure "Driver assistance computer (secondary): w038 cam failure";
CM_ SG_ 811 APS_w039_sdm_rcm_Mia "Driver assistance computer (secondary): w039 sdm rcm mia";
CM_ SG_ 811 APS_w040_autopilotAngleSaturated "Driver assistance computer (secondary): w040 autopilot angle saturated";
CM_ SG_ 811 APS_w041_autopilotRateSaturated "Driver assistance computer (secondary): w041 autopilot rate saturated";
CM_ SG_ 811 APS_w042_autopilotAborting "Driver assistance computer (secondary): w042 autopilot aborting";
CM_ SG_ 811 APS_w043_camLongRunTime "Driver assistance computer (secondary): w043 cam long run time";
CM_ SG_ 811 APS_w044_appMobileyeFailure "Driver assistance computer (secondary): w044 app mobileye failure";
CM_ SG_ 811 APS_w045_radMia "Driver assistance computer (secondary): w045 rad mia";
CM_ SG_ 811 APS_w046_eepromRecordAbsent "Driver assistance computer (secondary): w046 eeprom record absent";
CM_ SG_ 811 APS_w047_edrEvent "Driver assistance computer (secondary): w047 edr event";
CM_ SG_ 811 APS_w048_DAS_Features_Disabled "Driver assistance computer (secondary): w048 DAS features disabled";
CM_ SG_ 811 APS_w049_eyeqVersionMismatch "Driver assistance computer (secondary): w049 eyeq version mismatch";
CM_ SG_ 811 APS_w050_aeb_event "Driver assistance computer (secondary): w050 aeb event";
CM_ SG_ 811 APS_w051_radcEcuIssue "Driver assistance computer (secondary): w051 radc ecu issue";
CM_ SG_ 811 APS_w052_radcSensorIssue "Driver assistance computer (secondary): w052 radc sensor issue";
CM_ SG_ 811 APS_w053_radcCommIssue "Driver assistance computer (secondary): w053 radc comm issue";
CM_ SG_ 811 APS_w054_camAutofix "Driver assistance computer (secondary): w054 cam autofix";
CM_ SG_ 811 APS_w055_radcVersionMismatch "Driver assistance computer (secondary): w055 radc version mismatch";
CM_ SG_ 811 APS_w056_diMia "Driver assistance computer (secondary): w056 di mia";
CM_ SG_ 811 APS_w057_mcuMia "Driver assistance computer (secondary): w057 mcu mia";
CM_ SG_ 811 APS_w058_epbMia "Driver assistance computer (secondary): w058 epb mia";
CM_ SG_ 811 APS_w059_parkMia "Driver assistance computer (secondary): w059 park mia";
CM_ SG_ 811 APS_w060_fcw_event "Driver assistance computer (secondary): w060 fcw event";
CM_ SG_ 811 APS_w061_tasMia "Driver assistance computer (secondary): w061 tas mia";
CM_ SG_ 811 APS_w062_radcAlignment "Driver assistance computer (secondary): w062 radc alignment";
CM_ SG_ 811 APS_w063_parkVersionMismatch "Driver assistance computer (secondary): w063 park version mismatch";
CM_ SG_ 811 APS_w064_epasMia "Driver assistance computer (secondary): w064 epas mia";
CM_ BO_ 876 "Driver assistance computer (secondary) message: warning matrix1";
CM_ SG_ 876 APS_w065_deserializerOvercurrent "Driver assistance computer (secondary): w065 deserializer overcurrent";
CM_ SG_ 876 APS_w066_deserializerLockLost "Driver assistance computer (secondary): w066 deserializer lock lost";
CM_ SG_ 876 APS_w067_steeringAlignment "Driver assistance computer (secondary): w067 steering alignment";
CM_ SG_ 876 APS_w068_vlInconsistency "Driver assistance computer (secondary): w068 vl inconsistency";
CM_ SG_ 876 APS_w069_apcSpaceMasked "Driver assistance computer (secondary): w069 apc space masked";
CM_ SG_ 876 APS_w070_apcIncompleteCal "Driver assistance computer (secondary): w070 apc incomplete cal";
CM_ SG_ 876 APS_w071_selfparkStarted "Driver assistance computer (secondary): w071 selfpark started";
CM_ SG_ 876 APS_w072_selfparkComplete "Driver assistance computer (secondary): w072 selfpark complete";
CM_ SG_ 876 APS_w073_issueEscalatedLDW "Driver assistance computer (secondary): w073 issue escalated LDW";
CM_ SG_ 876 APS_w074_inPathStationaryObst "Driver assistance computer (secondary): w074 in path stationary obst";
CM_ SG_ 876 APS_w075_scMia "Driver assistance computer (secondary): w075 sc mia";
CM_ SG_ 876 APS_w076_mobilEyeSetC "Driver assistance computer (secondary): w076 mobil eye set c";
CM_ SG_ 876 APS_w077_pmmActive "Driver assistance computer (secondary): w077 pmm active";
CM_ SG_ 876 APS_w078_pmmActive2 "Driver assistance computer (secondary): w078 pmm active2";
CM_ SG_ 876 APS_w079_edrAvailable "Driver assistance computer (secondary): w079 edr available";
CM_ SG_ 876 APS_w080_accFailedActivation "Driver assistance computer (secondary): w080 acc failed activation";
CM_ SG_ 876 APS_w081_pmmActiveBraking "Driver assistance computer (secondary): w081 pmm active braking";
CM_ SG_ 876 APS_w082_inPathFSviolation "Driver assistance computer (secondary): w082 in path f sviolation";
CM_ SG_ 876 APS_w083_inPathRADObject "Driver assistance computer (secondary): w083 in path RAD object";
CM_ SG_ 876 APS_w084_pmmIPSO "Driver assistance computer (secondary): w084 pmm IPSO";
CM_ SG_ 876 APS_w085_pmmSteering "Driver assistance computer (secondary): w085 pmm steering";
CM_ SG_ 876 APS_w086_robCollision "Driver assistance computer (secondary): w086 rob collision";
CM_ SG_ 876 APS_w087_DEPRECATED "Driver assistance computer (secondary): w087 DEPRECATED";
CM_ SG_ 876 APS_w088_DEPRECATED "Driver assistance computer (secondary): w088 DEPRECATED";
CM_ SG_ 876 APS_w089_DEPRECATED "Driver assistance computer (secondary): w089 DEPRECATED";
CM_ SG_ 876 APS_w090_DEPRECATED "Driver assistance computer (secondary): w090 DEPRECATED";
CM_ SG_ 876 APS_w091_DEPRECATED "Driver assistance computer (secondary): w091 DEPRECATED";
CM_ SG_ 876 APS_w092_DEPRECATED "Driver assistance computer (secondary): w092 DEPRECATED";
CM_ SG_ 876 APS_w093_DEPRECATED "Driver assistance computer (secondary): w093 DEPRECATED";
CM_ SG_ 876 APS_w094_DEPRECATED "Driver assistance computer (secondary): w094 DEPRECATED";
CM_ SG_ 876 APS_w095_DEPRECATED "Driver assistance computer (secondary): w095 DEPRECATED";
CM_ SG_ 876 APS_w096_DEPRECATED "Driver assistance computer (secondary): w096 DEPRECATED";
CM_ SG_ 876 APS_w097_DEPRECATED "Driver assistance computer (secondary): w097 DEPRECATED";
CM_ SG_ 876 APS_w098_DEPRECATED "Driver assistance computer (secondary): w098 DEPRECATED";
CM_ SG_ 876 APS_w099_DEPRECATED "Driver assistance computer (secondary): w099 DEPRECATED";
CM_ SG_ 876 APS_w100_DEPRECATED "Driver assistance computer (secondary): w100 DEPRECATED";
CM_ SG_ 876 APS_w101_DEPRECATED "Driver assistance computer (secondary): w101 DEPRECATED";
CM_ SG_ 876 APS_w102_DEPRECATED "Driver assistance computer (secondary): w102 DEPRECATED";
CM_ SG_ 876 APS_w103_robExperimentalAEB "Driver assistance computer (secondary): w103 rob experimental AEB";
CM_ SG_ 876 APS_w104_DEPRECATED "Driver assistance computer (secondary): w104 DEPRECATED";
CM_ SG_ 876 APS_w105_DEPRECATED "Driver assistance computer (secondary): w105 DEPRECATED";
CM_ SG_ 876 APS_w106_torsionBarOffset "Driver assistance computer (secondary): w106 torsion bar offset";
CM_ BO_ 1113 "Driver assistance computer (secondary) message: warning matrix2";
CM_ SG_ 1113 APS_w129_ECU_Power_Issue "Driver assistance computer (secondary): w129 ECU power issue";
CM_ SG_ 1113 APS_w130_ECU_Thermal_Issue "Driver assistance computer (secondary): w130 ECU thermal issue";
CM_ SG_ 1113 APS_w131_trap_exception "Driver assistance computer (secondary): w131 trap exception";
CM_ SG_ 1113 APS_w132_appVersionMismatch "Driver assistance computer (secondary): w132 app version mismatch";
CM_ SG_ 1113 APS_w133_ETHSwitchError "Driver assistance computer (secondary): w133 ETH switch error";
CM_ SG_ 1113 APS_w134_appMia "Driver assistance computer (secondary): w134 app mia";
CM_ SG_ 1113 APS_w135_appCritical "Driver assistance computer (secondary): w135 app critical";
CM_ SG_ 1113 APS_w136_gpsDisabled "Driver assistance computer (secondary): w136 gps disabled";
CM_ SG_ 1113 APS_w137_gpsFaultReset "Driver assistance computer (secondary): w137 gps fault reset";
CM_ SG_ 1113 APS_w138_gpsComIssue "Driver assistance computer (secondary): w138 gps com issue";
CM_ SG_ 1113 APS_w139_udpBufferOverflow "Driver assistance computer (secondary): w139 udp buffer overflow";
CM_ SG_ 1113 APS_w140_vcfrontMiaVehicleBus "Driver assistance computer (secondary): w140 vcfront mia vehicle bus";
CM_ SG_ 1113 APS_w141_rcmMiaPartyBus "Driver assistance computer (secondary): w141 rcm mia party bus";
CM_ SG_ 1113 APS_w142_diMiaPartyBus "Driver assistance computer (secondary): w142 di mia party bus";
CM_ SG_ 1113 APS_w143_espMiaPartyBus "Driver assistance computer (secondary): w143 esp mia party bus";
CM_ SG_ 1113 APS_w144_vcleftMiaPartyBus "Driver assistance computer (secondary): w144 vcleft mia party bus";
CM_ SG_ 1113 APS_w145_vcrightMiaPartyBus "Driver assistance computer (secondary): w145 vcright mia party bus";
CM_ SG_ 1113 APS_w146_epas3pMiaPartyBus "Driver assistance computer (secondary): w146 epas3p mia party bus";
CM_ SG_ 1113 APS_w147_vcleftMiaVehBus "Driver assistance computer (secondary): w147 vcleft mia veh bus";
CM_ SG_ 1113 APS_w148_vcrightMiaVehBus "Driver assistance computer (secondary): w148 vcright mia veh bus";
CM_ SG_ 1113 APS_w149_epblMiaVehBus "Driver assistance computer (secondary): w149 epbl mia veh bus";
CM_ SG_ 1113 APS_w150_sccmMiaVehBus "Driver assistance computer (secondary): w150 sccm mia veh bus";
CM_ SG_ 1113 APS_w151_apRecovered "Driver assistance computer (secondary): w151 ap recovered";
CM_ SG_ 1113 APS_w152_gpsFusionStatus "Driver assistance computer (secondary): w152 gps fusion status";
CM_ SG_ 1113 APS_w153_eacInhibit "Driver assistance computer (secondary): w153 eac inhibit";
CM_ SG_ 1113 APS_w155_ethLwipError "Driver assistance computer (secondary): w155 eth lwip error";
CM_ SG_ 1113 APS_w156_lwipAssert "Driver assistance computer (secondary): w156 lwip assert";
CM_ SG_ 1113 APS_w157_autopilotReboot "Driver assistance computer (secondary): w157 autopilot reboot";
CM_ SG_ 1113 APS_w158_apbMia "Driver assistance computer (secondary): w158 apb mia";
CM_ SG_ 1113 APS_w159_apbCritical "Driver assistance computer (secondary): w159 apb critical";
CM_ SG_ 1113 APS_w160_apbVersionMismatch "Driver assistance computer (secondary): w160 apb version mismatch";
CM_ SG_ 1113 APS_w161_gpsAntennaDisconnected "Driver assistance computer (secondary): w161 gps antenna disconnected";
CM_ SG_ 1113 APS_w162_TurboA_DisRegPgoodErr "Driver assistance computer (secondary): w162 turbo a dis reg pgood err";
CM_ SG_ 1113 APS_w163_TurboA_DisRegNFault "Driver assistance computer (secondary): w163 turbo a dis reg n fault";
CM_ SG_ 1113 APS_w164_TurboA_12VFuseFault "Driver assistance computer (secondary): w164 turbo a 12 v fuse fault";
CM_ SG_ 1113 APS_w165_TurboA_Temp_NOS "Driver assistance computer (secondary): w165 turbo a temp NOS";
CM_ SG_ 1113 APS_w166_TurboA_SMSLockStepErr "Driver assistance computer (secondary): w166 turbo a SMS lock step err";
CM_ SG_ 1113 APS_w167_TurboA_TMU_Throttle "Driver assistance computer (secondary): w167 turbo a TMU throttle";
CM_ SG_ 1113 APS_w168_TurboA_SMS_WDOG "Driver assistance computer (secondary): w168 turbo a SMS WDOG";
CM_ SG_ 1113 APS_w169_TurboA_SCS_LKUP "Driver assistance computer (secondary): w169 turbo a SCS LKUP";
CM_ SG_ 1113 APS_w170_TurboA_A72_watchdog "Driver assistance computer (secondary): w170 turbo a A72 watchdog";
CM_ SG_ 1113 APS_w171_TurboA_SMS_taskUtilErr "Driver assistance computer (secondary): w171 turbo a SMS task util err";
CM_ SG_ 1113 APS_w172_apFeaturesUnavailable "Driver assistance computer (secondary): w172 ap features unavailable";
CM_ SG_ 1113 APS_w178_TurboB_DisRegPgoodErr "Driver assistance computer (secondary): w178 turbo b dis reg pgood err";
CM_ SG_ 1113 APS_w179_TurboB_DisRegNFault "Driver assistance computer (secondary): w179 turbo b dis reg n fault";
CM_ SG_ 1113 APS_w180_TurboB_12VFuseFault "Driver assistance computer (secondary): w180 turbo b 12 v fuse fault";
CM_ SG_ 1113 APS_w181_TurboB_Temp_NOS "Driver assistance computer (secondary): w181 turbo b temp NOS";
CM_ SG_ 1113 APS_w182_TurboB_SMSLockStepErr "Driver assistance computer (secondary): w182 turbo b SMS lock step err";
CM_ SG_ 1113 APS_w183_TurboB_TMU_Throttle "Driver assistance computer (secondary): w183 turbo b TMU throttle";
CM_ SG_ 1113 APS_w184_TurboB_SMS_WDOG "Driver assistance computer (secondary): w184 turbo b SMS WDOG";
CM_ SG_ 1113 APS_w185_TurboB_SCS_LKUP "Driver assistance computer (secondary): w185 turbo b SCS LKUP";
CM_ SG_ 1113 APS_w186_TurboB_A72_watchdog "Driver assistance computer (secondary): w186 turbo b A72 watchdog";
CM_ SG_ 1113 APS_w187_TurboB_SMS_taskUtilErr "Driver assistance computer (secondary): w187 turbo b SMS task util err";
CM_ SG_ 1113 APS_w188_otherTurboUartMIA "Driver assistance computer (secondary): w188 other turbo uart MIA";
CM_ SG_ 1113 APS_w189_vcfrontMiaPartyBus "Driver assistance computer (secondary): w189 vcfront mia party bus";
CM_ SG_ 1113 APS_w190_iboosterMia "Driver assistance computer (secondary): w190 ibooster mia";
CM_ SG_ 1113 APS_w191_timesyncError "Driver assistance computer (secondary): w191 timesync error";
CM_ SG_ 1113 APS_w192_CANFault "Driver assistance computer (secondary): w192 CAN fault";
CM_ BO_ 848 "Driver assistance computer (secondary) message: warning matrix3";
CM_ SG_ 848 APS_w193_camWindshieldUnclean "Driver assistance computer (secondary): w193 cam windshield unclean";
CM_ SG_ 848 APS_w194_accDriverResumeRqrd "Driver assistance computer (secondary): w194 acc driver resume rqrd";
CM_ SG_ 848 APS_w195_scwUnavailable "Driver assistance computer (secondary): w195 scw unavailable";
CM_ SG_ 848 APS_w196_stopSignWarning "Driver assistance computer (secondary): w196 stop sign warning";
CM_ SG_ 848 APS_w197_redLightWarning "Driver assistance computer (secondary): w197 red light warning";
CM_ SG_ 848 APS_w198_tsrUnavailable "Driver assistance computer (secondary): w198 tsr unavailable";
CM_ SG_ 848 APS_w199_apcAbort "Driver assistance computer (secondary): w199 apc abort";
CM_ SG_ 848 APS_w200_lcSlowdown "Driver assistance computer (secondary): w200 lc slowdown";
CM_ SG_ 848 APS_w201_lcAborting "Driver assistance computer (secondary): w201 lc aborting";
CM_ SG_ 848 APS_w202_scwNoisyEnvironment "Driver assistance computer (secondary): w202 scw noisy environment";
CM_ SG_ 848 APS_w203_apcActivation "Driver assistance computer (secondary): w203 apc activation";
CM_ SG_ 848 APS_w204_apcFinalFront "Driver assistance computer (secondary): w204 apc final front";
CM_ SG_ 848 APS_w205_apcFinalRear "Driver assistance computer (secondary): w205 apc final rear";
CM_ SG_ 848 APS_w206_autosteerNotEnabled "Driver assistance computer (secondary): w206 autosteer not enabled";
CM_ SG_ 848 APS_w207_autosteerUnavailable "Driver assistance computer (secondary): w207 autosteer unavailable";
CM_ SG_ 848 APS_w208_rackDetected "Driver assistance computer (secondary): w208 rack detected";
CM_ SG_ 848 APS_w209_autoSummonRequest "Driver assistance computer (secondary): w209 auto summon request";
CM_ SG_ 848 APS_w210_camObstrcted "Driver assistance computer (secondary): w210 cam obstrcted";
CM_ SG_ 848 APS_w211_accNoSeatBelt "Driver assistance computer (secondary): w211 acc no seat belt";
CM_ SG_ 848 APS_w212_lcUnavailableStrikeOut "Driver assistance computer (secondary): w212 lc unavailable strike out";
CM_ SG_ 848 APS_w213_autosteerStruckOut "Driver assistance computer (secondary): w213 autosteer struck out";
CM_ SG_ 848 APS_w214_driverNotIntracting "Driver assistance computer (secondary): w214 driver not intracting";
CM_ SG_ 848 APS_w215_contDriverNotIntracting "Driver assistance computer (secondary): w215 cont driver not intracting";
CM_ SG_ 848 APS_w216_driverOverriding "Driver assistance computer (secondary): w216 driver overriding";
CM_ SG_ 848 APS_w217_lcUnavailableSpeeding "Driver assistance computer (secondary): w217 lc unavailable speeding";
CM_ SG_ 848 APS_w218_lcSpeedExceededLimit "Driver assistance computer (secondary): w218 lc speed exceeded limit";
CM_ SG_ 848 APS_w219_lcTempUnavailableSpeed "Driver assistance computer (secondary): w219 lc temp unavailable speed";
CM_ SG_ 848 APS_w220_lcTempUnavailableRoad "Driver assistance computer (secondary): w220 lc temp unavailable road";
CM_ SG_ 848 APS_w221_accRadarBlind "Driver assistance computer (secondary): w221 acc radar blind";
CM_ SG_ 848 APS_w222_accCameraBlind "Driver assistance computer (secondary): w222 acc camera blind";
CM_ SG_ 848 APS_w223_accObjectInPath "Driver assistance computer (secondary): w223 acc object in path";
CM_ SG_ 848 APS_w224_accCameraCalibration "Driver assistance computer (secondary): w224 acc camera calibration";
CM_ SG_ 848 APS_w225_lcDegradedVisSpeedLmt "Driver assistance computer (secondary): w225 lc degraded vis speed lmt";
CM_ SG_ 848 APS_w226_lcCamCalNeededSpeedLmt "Driver assistance computer (secondary): w226 lc cam cal needed speed lmt";
CM_ SG_ 848 APS_w227_virtualWallBlocked "Driver assistance computer (secondary): w227 virtual wall blocked";
CM_ SG_ 848 APS_w228_DEPRECATED "Driver assistance computer (secondary): w228 DEPRECATED";
CM_ SG_ 848 APS_w229_alcUltrasoundDamaged "Driver assistance computer (secondary): w229 alc ultrasound damaged";
CM_ SG_ 848 APS_w230_alcUltrasoundBlocked "Driver assistance computer (secondary): w230 alc ultrasound blocked";
CM_ SG_ 848 APS_w231_idfEvent "Driver assistance computer (secondary): w231 idf event";
CM_ SG_ 848 APS_w232_laneChangeRequested "Driver assistance computer (secondary): w232 lane change requested";
CM_ SG_ 848 APS_w235_a72LoopDetected "Driver assistance computer (secondary): w235 a72 loop detected";
CM_ SG_ 848 APS_w236_canSharedMemError "Driver assistance computer (secondary): w236 can shared mem error";
CM_ SG_ 848 APS_w237_faultMgrEventDetected "Driver assistance computer (secondary): w237 fault mgr event detected";
CM_ SG_ 848 APS_w238_resetReason "Driver assistance computer (secondary): w238 reset reason";
CM_ SG_ 848 APS_w241_ddrInitFailures "Driver assistance computer (secondary): w241 ddr init failures";
CM_ SG_ 848 APS_w242_tripMBISTFailure "Driver assistance computer (secondary): w242 trip MBIST failure";
CM_ SG_ 848 APS_w243_tripHWErrorStatus "Driver assistance computer (secondary): w243 trip HW error status";
CM_ SG_ 848 APS_w244_gpuHWFaultStatus "Driver assistance computer (secondary): w244 gpu HW fault status";
CM_ SG_ 848 APS_w245_eloopRxFromUnexpectedSo "Driver assistance computer (secondary): w245 eloop rx from unexpected source MAC";
CM_ SG_ 848 APS_w246_ethloopSwitchPortLinkDo "Driver assistance computer (secondary): w246 ethloop switch port link down";
CM_ SG_ 848 APS_w247_ethernetFrameError "Driver assistance computer (secondary): w247 ethernet frame error";
CM_ SG_ 848 APS_w248_ethloopSwitchPoorSqi "Driver assistance computer (secondary): w248 ethloop switch poor sqi";
CM_ SG_ 848 APS_w249_ufsFailures "Driver assistance computer (secondary): w249 ufs failures";
CM_ SG_ 848 APS_w250_ethloopSwitchMemUsageTo "Driver assistance computer (secondary): w250 ethloop switch mem usage too high port2";
CM_ SG_ 848 APS_w251_ethloopSwitchMemUsageTo "Driver assistance computer (secondary): w251 ethloop switch mem usage too high port3";
CM_ SG_ 848 APS_w252_ethSwitchPortLinkDown "Driver assistance computer (secondary): w252 eth switch port link down";
CM_ SG_ 848 APS_w253_powerStateTimeout "Driver assistance computer (secondary): w253 power state timeout";
CM_ SG_ 848 APS_w254_sleepStateTimeout "Driver assistance computer (secondary): w254 sleep state timeout";
CM_ SG_ 848 APS_w255_bootHealth "Driver assistance computer (secondary): w255 boot health";
CM_ BO_ 784 "Driver assistance computer (secondary) message: warning matrix4";
CM_ SG_ 784 APS_w257_assertFailure "Driver assistance computer (secondary): w257 assert failure";
CM_ SG_ 784 APS_w258_qspiFlashSectorChecksum "Driver assistance computer (secondary): w258 qspi flash sector checksum mismatch";
CM_ SG_ 784 APS_w259_qspiFailure "Driver assistance computer (secondary): w259 qspi failure";
CM_ SG_ 784 APS_w260_pgoodFailure "Driver assistance computer (secondary): w260 pgood failure";
CM_ SG_ 784 APS_w261_vrmFaultGrpA "Driver assistance computer (secondary): w261 vrm fault grp a";
CM_ SG_ 784 APS_w262_vrmFaultGrpB "Driver assistance computer (secondary): w262 vrm fault grp b";
CM_ SG_ 784 APS_w263_vrmFaultGrpC "Driver assistance computer (secondary): w263 vrm fault grp c";
CM_ SG_ 784 APS_w264_ddrPhy0Failures "Driver assistance computer (secondary): w264 ddr phy0 failures";
CM_ SG_ 784 APS_w265_ddrPhy1Failures "Driver assistance computer (secondary): w265 ddr phy1 failures";
CM_ SG_ 784 APS_w266_ddrPhy2Failures "Driver assistance computer (secondary): w266 ddr phy2 failures";
CM_ SG_ 784 APS_w267_ddrPhy3Failures "Driver assistance computer (secondary): w267 ddr phy3 failures";
CM_ SG_ 784 APS_w268_ddrControllerFailures "Driver assistance computer (secondary): w268 ddr controller failures";
CM_ SG_ 784 APS_w269_ethSwitchRxPageCountToo "Driver assistance computer (secondary): w269 eth switch rx page count too high port0 3";
CM_ SG_ 784 APS_w270_ethSwitchRxPageCountToo "Driver assistance computer (secondary): w270 eth switch rx page count too high port4 7";
CM_ SG_ 784 APS_w271_ddrScheduler0EccErrors "Driver assistance computer (secondary): w271 ddr scheduler0 ecc errors";
CM_ SG_ 784 APS_w272_ddrScheduler1EccErrors "Driver assistance computer (secondary): w272 ddr scheduler1 ecc errors";
CM_ SG_ 784 APS_w273_ddrScheduler2EccErrors "Driver assistance computer (secondary): w273 ddr scheduler2 ecc errors";
CM_ SG_ 784 APS_w274_ddrScheduler3EccErrors "Driver assistance computer (secondary): w274 ddr scheduler3 ecc errors";
CM_ SG_ 784 APS_w275_ddrScheduler4EccErrors "Driver assistance computer (secondary): w275 ddr scheduler4 ecc errors";
CM_ SG_ 784 APS_w276_ddrScheduler5EccErrors "Driver assistance computer (secondary): w276 ddr scheduler5 ecc errors";
CM_ SG_ 784 APS_w277_ddrScheduler6EccErrors "Driver assistance computer (secondary): w277 ddr scheduler6 ecc errors";
CM_ SG_ 784 APS_w278_ddrScheduler7EccErrors "Driver assistance computer (secondary): w278 ddr scheduler7 ecc errors";
CM_ SG_ 784 APS_w279_ufsPartitionError "Driver assistance computer (secondary): w279 ufs partition error";
CM_ SG_ 784 APS_w280_pepsMia "Driver assistance computer (secondary): w280 peps mia";
CM_ SG_ 784 APS_w281_rsaMia "Driver assistance computer (secondary): w281 rsa mia";
CM_ SG_ 784 APS_w282_smmuError "Driver assistance computer (secondary): w282 smmu error";
CM_ SG_ 784 APS_w284_cam12VBuckBoostAPwrIssu "Driver assistance computer (secondary): w284 cam12 v buck boost a pwr issue";
CM_ SG_ 784 APS_w285_cam12VBuckBoostBPwrIssu "Driver assistance computer (secondary): w285 cam12 v buck boost b pwr issue";
CM_ SG_ 784 APS_w286_cam12VEFuseAPrimaryIssu "Driver assistance computer (secondary): w286 cam12 VE fuse a primary issue";
CM_ SG_ 784 APS_w287_cam12VEFuseASecondaryIs "Driver assistance computer (secondary): w287 cam12 VE fuse a secondary issue";
CM_ SG_ 784 APS_w288_brakeboosterMia "Driver assistance computer (secondary): w288 brakebooster mia";
CM_ SG_ 784 APS_w289_turboTemperatureWarning "Driver assistance computer (secondary): w289 turbo temperature warning";
CM_ SG_ 784 APS_w290_cam12VBuckBoostBPwrRing "Driver assistance computer (secondary): w290 cam12 v buck boost b pwr ringing";
CM_ BO_ 943 "BB ECU message: status";
CM_ SG_ 943 BB_statusChecksum "BB ECU: status checksum";
CM_ SG_ 943 BB_statusCounter "BB ECU: status counter";
CM_ SG_ 943 BB_sOutputRod "Reports the measured brake booster (BB) plunger piston position";
CM_ SG_ 943 BB_sOutputRodQF "Reports the BB_sOutputRod signal qualifier";
CM_ SG_ 943 BB_sInputRod "Reports the measured brake booster (BB) input rod stroke.";
CM_ SG_ 943 BB_sInputRodQF "Reports the BB_sInputRod signal qualifier.";
CM_ SG_ 943 BB_driverBrakeApply "Indicates whether the driver operates the brake pedal. Only active when the driver brakes, not when an external brake command implemented on brake booster (BB).";
CM_ SG_ 943 BB_driverBrakeApplyQF "Qualifier for BB_driverBrakeApply";
CM_ SG_ 943 BB_boosterStatus "Indication of the brake booster (BB) functional state";
CM_ SG_ 943 BB_warningLampRequest "Request from brake booster (BB) to enable the red brake lamp";
CM_ SG_ 943 BB_brakeFluidLevel "Indication of the brake fluid reservoir fluid level sensor status measured by the brake booster (BB).";
CM_ SG_ 943 BB_internalState "Indication of the brake booster (BB) internal state";
BA_DEF_ BO_ "GenMsgCycleTime" INT 0 3600000;
BA_DEF_ BO_ "GenMsgSendType" ENUM "Cyclic","NotUsed","NotUsed","NotUsed","NotUsed","NotUsed","NotUsed","IfActive","NoMsgSendType","NotUsed";
BA_DEF_ BO_ "VFrameFormat" ENUM "StandardCAN","ExtendedCAN","reserved","J1939PG","reserved","reserved","reserved","reserved","reserved","reserved","reserved","reserved","reserved","reserved","StandardCAN_FD","ExtendedCAN_FD";
BA_DEF_ BO_ "CANFD_BRS" ENUM "0","1";
BA_DEF_ SG_ "GenSigSNA" STRING;
BA_DEF_ SG_ "SystemSignalLongSymbol" STRING;
BA_DEF_ SG_ "Confidence" ENUM "validated","plausible","layout-only","contradicted";
BA_DEF_DEF_ "GenMsgCycleTime" 0;
BA_DEF_DEF_ "GenMsgSendType" "NoMsgSendType";
BA_DEF_DEF_ "VFrameFormat" "StandardCAN";
BA_DEF_DEF_ "CANFD_BRS" "1";
BA_DEF_DEF_ "GenSigSNA" "";
BA_DEF_DEF_ "SystemSignalLongSymbol" "";
BA_DEF_DEF_ "Confidence" "layout-only";
BA_ "GenMsgCycleTime" BO_ 1865 100;
BA_ "GenMsgSendType" BO_ 1865 0;
BA_ "GenMsgCycleTime" BO_ 2044 100;
BA_ "GenMsgSendType" BO_ 2044 0;
BA_ "GenMsgCycleTime" BO_ 970 500;
BA_ "GenMsgSendType" BO_ 970 0;
BA_ "GenMsgCycleTime" BO_ 1510 1000;
BA_ "GenMsgSendType" BO_ 1510 0;
BA_ "GenMsgCycleTime" BO_ 811 1000;
BA_ "GenMsgSendType" BO_ 811 0;
BA_ "GenMsgCycleTime" BO_ 876 1000;
BA_ "GenMsgSendType" BO_ 876 0;
BA_ "GenMsgCycleTime" BO_ 1113 1000;
BA_ "GenMsgSendType" BO_ 1113 0;
BA_ "GenMsgCycleTime" BO_ 848 1000;
BA_ "GenMsgSendType" BO_ 848 0;
BA_ "GenMsgCycleTime" BO_ 784 1000;
BA_ "GenMsgSendType" BO_ 784 0;
BA_ "GenMsgCycleTime" BO_ 943 10;
BA_ "GenMsgSendType" BO_ 943 0;
BA_ "Confidence" SG_ 1865 APS_A_lowPowerRequest 0;
BA_ "Confidence" SG_ 1865 APS_A_lowPowerRequestor 0;
BA_ "Confidence" SG_ 1865 APS_A_forcePowerOffRequest 0;
BA_ "Confidence" SG_ 1865 APS_B_lowPowerRequest 0;
BA_ "Confidence" SG_ 1865 APS_B_lowPowerRequestor 0;
BA_ "Confidence" SG_ 1865 APS_B_forcePowerOffRequest 0;
BA_ "Confidence" SG_ 2044 APS_primaryTurbo 0;
BA_ "Confidence" SG_ 2044 APS_A_arbState 0;
BA_ "Confidence" SG_ 2044 APS_A_powerState 0;
BA_ "Confidence" SG_ 2044 APS_A_sleepState 0;
BA_ "Confidence" SG_ 2044 APS_A_resetState 0;
BA_ "Confidence" SG_ 2044 APS_A_faultState 0;
BA_ "Confidence" SG_ 2044 APS_secondaryTurbo 0;
BA_ "Confidence" SG_ 2044 APS_B_arbState 0;
BA_ "Confidence" SG_ 2044 APS_B_powerState 0;
BA_ "Confidence" SG_ 2044 APS_B_sleepState 0;
BA_ "Confidence" SG_ 2044 APS_B_resetState 0;
BA_ "Confidence" SG_ 2044 APS_B_faultState 0;
BA_ "Confidence" SG_ 2044 APS_autosteerMonitorState 1;
BA_ "Confidence" SG_ 970 APS_appStatusMonitorState 0;
BA_ "Confidence" SG_ 970 APS_vehBehaviorState 0;
BA_ "Confidence" SG_ 970 APS_canMaster 0;
BA_ "GenSigSNA" SG_ 970 APS_canMaster "3";
BA_ "Confidence" SG_ 970 APS_appGpioState 0;
BA_ "Confidence" SG_ 970 APS_eacInternalState 0;
BA_ "Confidence" SG_ 970 APS_switchState 0;
BA_ "Confidence" SG_ 970 APS_apbStatusMonitorState 0;
BA_ "Confidence" SG_ 970 APS_apbGpioState 0;
BA_ "Confidence" SG_ 970 APS_statusCounter 0;
BA_ "Confidence" SG_ 970 APS_locLimitReason 0;
BA_ "Confidence" SG_ 970 APS_appPowerStateRequest 0;
BA_ "Confidence" SG_ 970 APS_appPowerStateReason 0;
BA_ "Confidence" SG_ 970 APS_apbPowerStateRequest 1;
BA_ "Confidence" SG_ 970 APS_apbPowerStateReason 1;
BA_ "Confidence" SG_ 970 APS_heaterStateDebug 1;
BA_ "GenSigSNA" SG_ 970 APS_heaterStateDebug "7";
BA_ "Confidence" SG_ 970 APS_gpsAntennaState 1;
BA_ "Confidence" SG_ 970 APS_arbState 1;
BA_ "Confidence" SG_ 970 APS_socPowerOperatingMode 1;
BA_ "Confidence" SG_ 970 APS_otherArbState 1;
BA_ "Confidence" SG_ 1510 APS_A_cam12v0Voltage 0;
BA_ "GenSigSNA" SG_ 1510 APS_A_cam12v0Voltage "4095";
BA_ "Confidence" SG_ 1510 APS_B_cam12v0Voltage 0;
BA_ "GenSigSNA" SG_ 1510 APS_B_cam12v0Voltage "4095";
BA_ "Confidence" SG_ 1510 APS_A_turboMaxTemperature 0;
BA_ "GenSigSNA" SG_ 1510 APS_A_turboMaxTemperature "128";
BA_ "Confidence" SG_ 1510 APS_A_turboProbeType 0;
BA_ "GenSigSNA" SG_ 1510 APS_A_turboProbeType "63";
BA_ "Confidence" SG_ 1510 APS_B_turboMaxTemperature 0;
BA_ "GenSigSNA" SG_ 1510 APS_B_turboMaxTemperature "128";
BA_ "Confidence" SG_ 1510 APS_B_turboProbeType 0;
BA_ "GenSigSNA" SG_ 1510 APS_B_turboProbeType "63";
BA_ "SystemSignalLongSymbol" SG_ 848 APS_w245_eloopRxFromUnexpectedSo "APS_w245_eloopRxFromUnexpectedSourceMAC";
BA_ "SystemSignalLongSymbol" SG_ 848 APS_w246_ethloopSwitchPortLinkDo "APS_w246_ethloopSwitchPortLinkDown";
BA_ "SystemSignalLongSymbol" SG_ 848 APS_w250_ethloopSwitchMemUsageTo "APS_w250_ethloopSwitchMemUsageTooHighPort2";
BA_ "SystemSignalLongSymbol" SG_ 848 APS_w251_ethloopSwitchMemUsageTo "APS_w251_ethloopSwitchMemUsageTooHighPort3";
BA_ "SystemSignalLongSymbol" SG_ 784 APS_w258_qspiFlashSectorChecksum "APS_w258_qspiFlashSectorChecksumMismatch";
BA_ "SystemSignalLongSymbol" SG_ 784 APS_w269_ethSwitchRxPageCountToo "APS_w269_ethSwitchRxPageCountTooHighPort0_3";
BA_ "SystemSignalLongSymbol" SG_ 784 APS_w270_ethSwitchRxPageCountToo "APS_w270_ethSwitchRxPageCountTooHighPort4_7";
BA_ "SystemSignalLongSymbol" SG_ 784 APS_w284_cam12VBuckBoostAPwrIssu "APS_w284_cam12VBuckBoostAPwrIssue";
BA_ "SystemSignalLongSymbol" SG_ 784 APS_w285_cam12VBuckBoostBPwrIssu "APS_w285_cam12VBuckBoostBPwrIssue";
BA_ "SystemSignalLongSymbol" SG_ 784 APS_w286_cam12VEFuseAPrimaryIssu "APS_w286_cam12VEFuseAPrimaryIssue";
BA_ "SystemSignalLongSymbol" SG_ 784 APS_w287_cam12VEFuseASecondaryIs "APS_w287_cam12VEFuseASecondaryIssue";
BA_ "SystemSignalLongSymbol" SG_ 784 APS_w290_cam12VBuckBoostBPwrRing "APS_w290_cam12VBuckBoostBPwrRinging";
BA_ "Confidence" SG_ 943 BB_statusChecksum 0;
BA_ "Confidence" SG_ 943 BB_statusCounter 0;
BA_ "Confidence" SG_ 943 BB_sOutputRod 0;
BA_ "Confidence" SG_ 943 BB_sOutputRodQF 0;
BA_ "Confidence" SG_ 943 BB_sInputRod 0;
BA_ "Confidence" SG_ 943 BB_sInputRodQF 0;
BA_ "Confidence" SG_ 943 BB_driverBrakeApply 0;
BA_ "Confidence" SG_ 943 BB_driverBrakeApplyQF 0;
BA_ "Confidence" SG_ 943 BB_boosterStatus 0;
BA_ "Confidence" SG_ 943 BB_warningLampRequest 0;
BA_ "Confidence" SG_ 943 BB_brakeFluidLevel 0;
BA_ "Confidence" SG_ 943 BB_internalState 0;
VAL_ 1865 APS_A_lowPowerRequest 5 "APS_LOW_POWER_COLD_RESET" 4 "APS_LOW_POWER_SOC_WARM_RESET" 3 "APS_LOW_POWER_AP_WARM_RESET" 2 "APS_LOW_POWER_OFF" 1 "APS_LOW_POWER_SUSPEND" 0 "APS_LOW_POWER_NONE" ;
VAL_ 1865 APS_A_lowPowerRequestor 10 "APS_LOW_POWER_REQ_COUNT" 9 "APS_LOW_POWER_REQ_SGK_PGOOD_IRQ" 8 "APS_LOW_POWER_REQ_SGK_CONSOLE" 7 "APS_LOW_POWER_REQ_SGK_SLEEP" 6 "APS_LOW_POWER_REQ_SGK_UDS" 5 "APS_LOW_POWER_REQ_SGK_BRIDGE" 4 "APS_LOW_POWER_REQ_SGK_FM" 3 "APS_LOW_POWER_REQ_SGK_POWER" 2 "APS_LOW_POWER_REQ_AP_MAILBOX" 1 "APS_LOW_POWER_REQ_AP_ATF" 0 "APS_LOW_POWER_REQ_NONE" ;
VAL_ 1865 APS_B_lowPowerRequest 5 "APS_LOW_POWER_COLD_RESET" 4 "APS_LOW_POWER_SOC_WARM_RESET" 3 "APS_LOW_POWER_AP_WARM_RESET" 2 "APS_LOW_POWER_OFF" 1 "APS_LOW_POWER_SUSPEND" 0 "APS_LOW_POWER_NONE" ;
VAL_ 1865 APS_B_lowPowerRequestor 10 "APS_LOW_POWER_REQ_COUNT" 9 "APS_LOW_POWER_REQ_SGK_PGOOD_IRQ" 8 "APS_LOW_POWER_REQ_SGK_CONSOLE" 7 "APS_LOW_POWER_REQ_SGK_SLEEP" 6 "APS_LOW_POWER_REQ_SGK_UDS" 5 "APS_LOW_POWER_REQ_SGK_BRIDGE" 4 "APS_LOW_POWER_REQ_SGK_FM" 3 "APS_LOW_POWER_REQ_SGK_POWER" 2 "APS_LOW_POWER_REQ_AP_MAILBOX" 1 "APS_LOW_POWER_REQ_AP_ATF" 0 "APS_LOW_POWER_REQ_NONE" ;
VAL_ 2044 APS_primaryTurbo 2 "TURBO_UNKNOWN" 1 "TURBO_B" 0 "TURBO_A" ;
VAL_ 2044 APS_A_arbState 7 "ARB_STATE_COUNT" 6 "ARB_STATE_UNKNOWN" 5 "ARB_STATE_MIA" 4 "ARB_STATE_FAULT" 3 "ARB_STATE_SECONDARY" 2 "ARB_STATE_PRIMARY" 1 "ARB_STATE_IDLE" 0 "ARB_STATE_INIT" ;
VAL_ 2044 APS_A_powerState 28 "POWER_STATE_AP_FORCE_POWER_OFF" 27 "POWER_STATE_AP_WAIT_FOR_SHUTDOWN_ABORT" 26 "POWER_STATE_AP_IN_LINUX" 25 "POWER_STATE_AP_IDLE" 24 "POWER_STATE_VEH_BOOTING" 23 "POWER_STATE_UNKNOWN" 22 "POWER_STATE_MIA" 21 "POWER_STATE_FAULT" 20 "POWER_STATE_SOC_OFF_ABORT" 19 "POWER_STATE_SOC_OFF" 18 "POWER_STATE_SOC_OFF_READY" 17 "POWER_STATE_AP_SUSPENDED" 16 "POWER_STATE_AP_OFF_ABORT_WAIT_FOR_ACK" 15 "POWER_STATE_AP_OFF_ABORT" 14 "POWER_STATE_AP_OFF_READY_WAIT_FOR_RESPONSE" 13 "POWER_STATE_AP_OFF_READY_WAIT_FOR_ACK" 12 "POWER_STATE_AP_OFF_READY" 11 "POWER_STATE_AP_OFF_PREPARE" 10 "POWER_STATE_AP_WAIT_FOR_SHUTDOWN" 9 "POWER_STATE_AP_ON" 8 "POWER_STATE_AP_IN_COREBOOT" 7 "POWER_STATE_AP_BOOTING" 6 "POWER_STATE_AP_ON_READY_WAIT_FOR_RESPONSE" 5 "POWER_STATE_AP_ON_READY_WAIT_FOR_ACK" 4 "POWER_STATE_AP_ON_READY" 3 "POWER_STATE_AP_ON_PREPARE_WAIT_FOR_RESPONSE" 2 "POWER_STATE_AP_ON_PREPARE_WAIT_FOR_ACK" 1 "POWER_STATE_AP_ON_PREPARE" 0 "POWER_STATE_IDLE" ;
VAL_ 2044 APS_A_sleepState 9 "SLEEP_STATE_COUNT" 8 "SLEEP_STATE_UNKNOWN" 7 "SLEEP_STATE_MIA" 6 "SLEEP_STATE_FAULT" 5 "SLEEP_STATE_ABORT" 4 "SLEEP_STATE_SLEEPING" 3 "SLEEP_STATE_GOING_TO_SLEEP" 2 "SLEEP_STATE_READY" 1 "SLEEP_STATE_WAIT_FOR_BUS_SILENCE" 0 "SLEEP_STATE_IDLE" ;
VAL_ 2044 APS_A_resetState 5 "RESET_STATE_COUNT" 4 "RESET_STATE_UNKNOWN" 3 "RESET_STATE_MIA" 2 "RESET_STATE_FAULT" 1 "RESET_STATE_RESETTING" 0 "RESET_STATE_NOT_RESETTING" ;
VAL_ 2044 APS_A_faultState 27 "FAULT_STATE_COUNT" 26 "FAULT_STATE_UNKNOWN" 25 "FAULT_STATE_MIA" 24 "FAULT_STATE_UNEXPECTED" 23 "FAULT_STATE_SCS" 22 "FAULT_STATE_SOFTWARE_FAULT" 21 "FAULT_STATE_TRIP1_FAULT" 20 "FAULT_STATE_TRIP0_FAULT" 19 "FAULT_STATE_WDT" 18 "FAULT_STATE_CPU_FAULT" 17 "FAULT_STATE_DROOP_TRIP" 16 "FAULT_STATE_DROOP_GPU" 15 "FAULT_STATE_DROOP_CPUCL2" 14 "FAULT_STATE_DROOP_CPUCL1" 13 "FAULT_STATE_DROOP_CPUCL0" 12 "FAULT_STATE_MIF_ECC_AP" 11 "FAULT_STATE_MIF7_DFI_ALERT" 10 "FAULT_STATE_MIF6_DFI_ALERT" 9 "FAULT_STATE_MIF5_DFI_ALERT" 8 "FAULT_STATE_MIF4_DFI_ALERT" 7 "FAULT_STATE_MIF3_DFI_ALERT" 6 "FAULT_STATE_MIF2_DFI_ALERT" 5 "FAULT_STATE_MIF1_DFI_ALERT" 4 "FAULT_STATE_MIF0_DFI_ALERT" 3 "FAULT_STATE_MIF_ECC_UNCORRECTED" 2 "FAULT_STATE_MIF_ECC_CORRECTED" 1 "FAULT_STATE_GIC" 0 "FAULT_STATE_NONE" ;
VAL_ 2044 APS_secondaryTurbo 2 "TURBO_UNKNOWN" 1 "TURBO_B" 0 "TURBO_A" ;
VAL_ 2044 APS_B_arbState 7 "ARB_STATE_COUNT" 6 "ARB_STATE_UNKNOWN" 5 "ARB_STATE_MIA" 4 "ARB_STATE_FAULT" 3 "ARB_STATE_SECONDARY" 2 "ARB_STATE_PRIMARY" 1 "ARB_STATE_IDLE" 0 "ARB_STATE_INIT" ;
VAL_ 2044 APS_B_powerState 28 "POWER_STATE_AP_FORCE_POWER_OFF" 27 "POWER_STATE_AP_WAIT_FOR_SHUTDOWN_ABORT" 26 "POWER_STATE_AP_IN_LINUX" 25 "POWER_STATE_AP_IDLE" 24 "POWER_STATE_VEH_BOOTING" 23 "POWER_STATE_UNKNOWN" 22 "POWER_STATE_MIA" 21 "POWER_STATE_FAULT" 20 "POWER_STATE_SOC_OFF_ABORT" 19 "POWER_STATE_SOC_OFF" 18 "POWER_STATE_SOC_OFF_READY" 17 "POWER_STATE_AP_SUSPENDED" 16 "POWER_STATE_AP_OFF_ABORT_WAIT_FOR_ACK" 15 "POWER_STATE_AP_OFF_ABORT" 14 "POWER_STATE_AP_OFF_READY_WAIT_FOR_RESPONSE" 13 "POWER_STATE_AP_OFF_READY_WAIT_FOR_ACK" 12 "POWER_STATE_AP_OFF_READY" 11 "POWER_STATE_AP_OFF_PREPARE" 10 "POWER_STATE_AP_WAIT_FOR_SHUTDOWN" 9 "POWER_STATE_AP_ON" 8 "POWER_STATE_AP_IN_COREBOOT" 7 "POWER_STATE_AP_BOOTING" 6 "POWER_STATE_AP_ON_READY_WAIT_FOR_RESPONSE" 5 "POWER_STATE_AP_ON_READY_WAIT_FOR_ACK" 4 "POWER_STATE_AP_ON_READY" 3 "POWER_STATE_AP_ON_PREPARE_WAIT_FOR_RESPONSE" 2 "POWER_STATE_AP_ON_PREPARE_WAIT_FOR_ACK" 1 "POWER_STATE_AP_ON_PREPARE" 0 "POWER_STATE_IDLE" ;
VAL_ 2044 APS_B_sleepState 9 "SLEEP_STATE_COUNT" 8 "SLEEP_STATE_UNKNOWN" 7 "SLEEP_STATE_MIA" 6 "SLEEP_STATE_FAULT" 5 "SLEEP_STATE_ABORT" 4 "SLEEP_STATE_SLEEPING" 3 "SLEEP_STATE_GOING_TO_SLEEP" 2 "SLEEP_STATE_READY" 1 "SLEEP_STATE_WAIT_FOR_BUS_SILENCE" 0 "SLEEP_STATE_IDLE" ;
VAL_ 2044 APS_B_resetState 5 "RESET_STATE_COUNT" 4 "RESET_STATE_UNKNOWN" 3 "RESET_STATE_MIA" 2 "RESET_STATE_FAULT" 1 "RESET_STATE_RESETTING" 0 "RESET_STATE_NOT_RESETTING" ;
VAL_ 2044 APS_B_faultState 27 "FAULT_STATE_COUNT" 26 "FAULT_STATE_UNKNOWN" 25 "FAULT_STATE_MIA" 24 "FAULT_STATE_UNEXPECTED" 23 "FAULT_STATE_SCS" 22 "FAULT_STATE_SOFTWARE_FAULT" 21 "FAULT_STATE_TRIP1_FAULT" 20 "FAULT_STATE_TRIP0_FAULT" 19 "FAULT_STATE_WDT" 18 "FAULT_STATE_CPU_FAULT" 17 "FAULT_STATE_DROOP_TRIP" 16 "FAULT_STATE_DROOP_GPU" 15 "FAULT_STATE_DROOP_CPUCL2" 14 "FAULT_STATE_DROOP_CPUCL1" 13 "FAULT_STATE_DROOP_CPUCL0" 12 "FAULT_STATE_MIF_ECC_AP" 11 "FAULT_STATE_MIF7_DFI_ALERT" 10 "FAULT_STATE_MIF6_DFI_ALERT" 9 "FAULT_STATE_MIF5_DFI_ALERT" 8 "FAULT_STATE_MIF4_DFI_ALERT" 7 "FAULT_STATE_MIF3_DFI_ALERT" 6 "FAULT_STATE_MIF2_DFI_ALERT" 5 "FAULT_STATE_MIF1_DFI_ALERT" 4 "FAULT_STATE_MIF0_DFI_ALERT" 3 "FAULT_STATE_MIF_ECC_UNCORRECTED" 2 "FAULT_STATE_MIF_ECC_CORRECTED" 1 "FAULT_STATE_GIC" 0 "FAULT_STATE_NONE" ;
VAL_ 2044 APS_autosteerMonitorState 4 "COUNT" 3 "TOI_TRIGGER" 2 "WAIT_FOR_MIA" 1 "ACTIVE" 0 "IDLE" ;
VAL_ 970 APS_appStatusMonitorState 7 "STATUS_MONITOR_NUM_STATES" 6 "STATUS_MONITOR_STATE_RECOVERY" 5 "STATUS_MONITOR_STATE_SHUTTING_DOWN" 4 "STATUS_MONITOR_STATE_CRITICAL" 3 "STATUS_MONITOR_STATE_NOMINAL" 2 "STATUS_MONITOR_STATE_INIT" 1 "STATUS_MONITOR_STATE_PWR_OFF" 0 "STATUS_MONITOR_STATE_UNKNOWN" ;
VAL_ 970 APS_vehBehaviorState 8 "VEH_BEHAVIOR_NUM_STATES" 7 "VEH_BEHAVIOR_STATE_SYSTEM_FAULT" 6 "VEH_BEHAVIOR_STATE_APS_OVERRIDE" 5 "VEH_BEHAVIOR_STATE_APS_FAIL_SAFE" 4 "VEH_BEHAVIOR_STATE_APS_BRIDGE_APB" 3 "VEH_BEHAVIOR_STATE_APS_BRIDGE_APP" 2 "VEH_BEHAVIOR_STATE_APS_CONTROL" 1 "VEH_BEHAVIOR_STATE_APS_AVAILABLE" 0 "VEH_BEHAVIOR_STATE_UNKNOWN" ;
VAL_ 970 APS_canMaster 3 "CAN_MASTER_SNA" 2 "CAN_MASTER_APB" 1 "CAN_MASTER_APP" 0 "CAN_MASTER_APS" ;
VAL_ 970 APS_appGpioState 3 "AP_GPIO_STATE_HEALTHY" 2 "AP_GPIO_STATE_CRITICAL" 1 "AP_GPIO_STATE_DISABLED" 0 "AP_GPIO_STATE_PWR_DOWN_REBOOT" ;
VAL_ 970 APS_eacInternalState 7 "APS_EAC_NUM_STATES" 6 "APS_EAC_STATE_LSS" 5 "APS_EAC_STATE_OVERRIDE" 4 "APS_EAC_STATE_INHIBIT" 3 "APS_EAC_STATE_AUTOPARK" 2 "APS_EAC_STATE_CONTINUOUS" 1 "APS_EAC_STATE_MOMENTARY" 0 "APS_EAC_STATE_INIT" ;
VAL_ 970 APS_apbStatusMonitorState 7 "STATUS_MONITOR_NUM_STATES" 6 "STATUS_MONITOR_STATE_RECOVERY" 5 "STATUS_MONITOR_STATE_SHUTTING_DOWN" 4 "STATUS_MONITOR_STATE_CRITICAL" 3 "STATUS_MONITOR_STATE_NOMINAL" 2 "STATUS_MONITOR_STATE_INIT" 1 "STATUS_MONITOR_STATE_PWR_OFF" 0 "STATUS_MONITOR_STATE_UNKNOWN" ;
VAL_ 970 APS_apbGpioState 3 "AP_GPIO_STATE_HEALTHY" 2 "AP_GPIO_STATE_CRITICAL" 1 "AP_GPIO_STATE_DISABLED" 0 "AP_GPIO_STATE_PWR_DOWN_REBOOT" ;
VAL_ 970 APS_locLimitReason 7 "LOC_LIMITS_EXTENDED" 6 "LOC_MONITOR_UNAVAILABLE" 5 "NO_RADAR_TARGET" 4 "RADAR_NOT_HEALTHY" 3 "PRIMARY_AP_NOT_HEALTHY" 2 "ACC_AND_AEB_UNAVAILABLE" 1 "NOT_IN_DRIVE" 0 "NOMINAL_DEFAULT" ;
VAL_ 970 APS_appPowerStateRequest 3 "AP_POWER_STATE_SLEEP" 2 "AP_POWER_STATE_SUSPEND" 1 "AP_POWER_STATE_SENTRY" 0 "AP_POWER_STATE_NOMINAL" ;
VAL_ 970 APS_appPowerStateReason 12 "UI_SUMMON_STANDBY_MODE_ENABLED" 11 "SLEEP_REQUEST_RECVD" 10 "AP_POWER_REQUEST_OVERHEATED" 9 "LOADSHED_POWER_REQUEST_PENDING" 8 "VC_POWER_REQUEST" 7 "AP_POWER_REQUEST_OVERRIDE" 6 "AP_POWER_REQUEST_OVERHEATING" 5 "AP_POWER_REQUEST_HYSTERESIS" 4 "GTW_GOTO_FULL_POWER" 3 "AP_NOT_IN_PARK" 2 "AP_NM_REASON_SET" 1 "AP_WDOG_UNHEALTHY" 0 "UI_POWER_STATE_REQUEST" ;
VAL_ 970 APS_apbPowerStateRequest 3 "AP_POWER_STATE_SLEEP" 2 "AP_POWER_STATE_SUSPEND" 1 "AP_POWER_STATE_SENTRY" 0 "AP_POWER_STATE_NOMINAL" ;
VAL_ 970 APS_apbPowerStateReason 12 "UI_SUMMON_STANDBY_MODE_ENABLED" 11 "SLEEP_REQUEST_RECVD" 10 "AP_POWER_REQUEST_OVERHEATED" 9 "LOADSHED_POWER_REQUEST_PENDING" 8 "VC_POWER_REQUEST" 7 "AP_POWER_REQUEST_OVERRIDE" 6 "AP_POWER_REQUEST_OVERHEATING" 5 "AP_POWER_REQUEST_HYSTERESIS" 4 "GTW_GOTO_FULL_POWER" 3 "AP_NOT_IN_PARK" 2 "AP_NM_REASON_SET" 1 "AP_WDOG_UNHEALTHY" 0 "UI_POWER_STATE_REQUEST" ;
VAL_ 970 APS_heaterStateDebug 7 "APS_HEATER_SNA" 4 "APS_HEATER_FAULT_SHORT" 3 "APS_HEATER_FAULT_OPEN" 2 "APS_HEATER_ON_NOT_HEATING" 1 "APS_HEATER_ON_HEATING" 0 "APS_HEATER_OFF" ;
VAL_ 970 APS_gpsAntennaState 2 "GPS_ANTENNA_CONNECTED" 1 "GPS_ANTENNA_UNKNOWN" 0 "GPS_ANTENNA_DISCONNECTED" ;
VAL_ 970 APS_arbState 7 "ARB_STATE_N_COUNT" 6 "ARB_STATE_N_UNKNOWN" 5 "ARB_STATE_N_MIA" 4 "ARB_STATE_N_FAULT" 3 "ARB_STATE_N_SECONDARY" 2 "ARB_STATE_N_PRIMARY" 1 "ARB_STATE_N_IDLE" 0 "ARB_STATE_N_INIT" ;
VAL_ 970 APS_socPowerOperatingMode 2 "APS_DUAL_SOC" 1 "APS_SINGLE_SOC" 0 "APS_UNKNOWN" ;
VAL_ 970 APS_otherArbState 7 "ARB_STATE_N_COUNT" 6 "ARB_STATE_N_UNKNOWN" 5 "ARB_STATE_N_MIA" 4 "ARB_STATE_N_FAULT" 3 "ARB_STATE_N_SECONDARY" 2 "ARB_STATE_N_PRIMARY" 1 "ARB_STATE_N_IDLE" 0 "ARB_STATE_N_INIT" ;
VAL_ 1510 APS_A_cam12v0Voltage 4095 "SNA" ;
VAL_ 1510 APS_B_cam12v0Voltage 4095 "SNA" ;
VAL_ 1510 APS_A_turboMaxTemperature -128 "SNA" ;
VAL_ 1510 APS_A_turboProbeType 63 "SNA" ;
VAL_ 1510 APS_B_turboMaxTemperature -128 "SNA" ;
VAL_ 1510 APS_B_turboProbeType 63 "SNA" ;
VAL_ 943 BB_sOutputRodQF 2 "Faulty" 1 "Normal" 0 "NotInit_orOff" ;
VAL_ 943 BB_sInputRodQF 2 "Faulty" 1 "Normal" 0 "NotInit_orOff" ;
VAL_ 943 BB_driverBrakeApply 1 "DRIVER_APPLYING_BRAKES" 0 "BRAKES_NOT_APPLIED" ;
VAL_ 943 BB_driverBrakeApplyQF 2 "Faulty" 1 "Normal" 0 "NotInit_orOff" ;
VAL_ 943 BB_boosterStatus 6 "ACTUATION" 5 "READY" 4 "ACTIVE_GOOD_CHECK" 3 "DIAGNOSTIC" 2 "FAILURE" 1 "INIT" 0 "OFF" ;
VAL_ 943 BB_warningLampRequest 2 "RED_BRAKE_LAMP_REQUEST" 1 "YELLOW_BRAKE_LAMP_REQUEST" 0 "NO_LAMP_REQUEST" ;
VAL_ 943 BB_brakeFluidLevel 3 "BRAKE_FLUID_LEVEL_INVALID" 2 "BRAKE_FLUID_LEVEL_NORMAL" 1 "BRAKE_FLUID_LEVEL_LOW" 0 "BRAKE_FLUID_LEVEL_UNKNOWN" ;
VAL_ 943 BB_internalState 7 "READY_TO_SHUTDOWN" 6 "POST_DRIVE_CHECK" 5 "TRANSITION_TO_IDLE" 4 "DIAGNOSTIC" 3 "EXTERNAL_BRAKE_REQUEST" 2 "LOCAL_BRAKE_REQUEST" 1 "PRE_DRIVE_CHECK" 0 "NO_MODE_ACTIVE" ;
